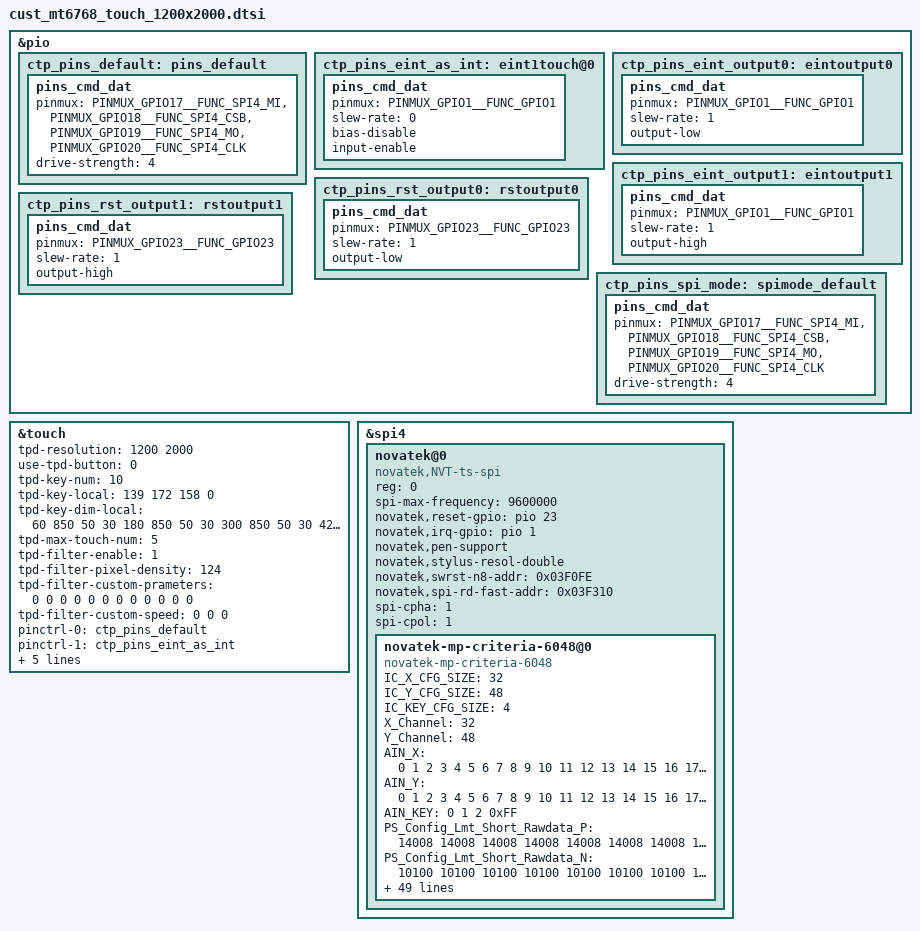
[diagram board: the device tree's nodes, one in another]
/* SPDX-License-Identifier: GPL-2.0 */
/*
 * Copyright (c) 2019 MediaTek Inc.
 *
 * This program is free software; you can redistribute it and/or modify
 * it under the terms of the GNU General Public License version 2 as
 * published by the Free Software Foundation.
 *
 * This program is distributed in the hope that it will be useful,
 * but WITHOUT ANY WARRANTY; without even the implied warranty of
 * MERCHANTABILITY or FITNESS FOR A PARTICULAR PURPOSE.  See the
 * GNU General Public License for more details.
 */
/* TOUCH start */

&pio {
	ctp_pins_default: pins_default {
		pins_cmd_dat {
			pinmux = <PINMUX_GPIO17__FUNC_SPI4_MI>,
				<PINMUX_GPIO18__FUNC_SPI4_CSB>,
				<PINMUX_GPIO19__FUNC_SPI4_MO>,
				<PINMUX_GPIO20__FUNC_SPI4_CLK>;
			drive-strength=<4>;
		};
	};
	ctp_pins_eint_as_int: eint1touch@0 {
		pins_cmd_dat {
			pinmux = <PINMUX_GPIO1__FUNC_GPIO1>;
			slew-rate = <0>;
			bias-disable;
			input-enable;
		};
	};
	ctp_pins_eint_output0: eintoutput0 {
		pins_cmd_dat {
			pinmux = <PINMUX_GPIO1__FUNC_GPIO1>;
			slew-rate = <1>;
			output-low;
		};
	};
	ctp_pins_eint_output1: eintoutput1 {
		pins_cmd_dat {
			pinmux = <PINMUX_GPIO1__FUNC_GPIO1>;
			slew-rate = <1>;
			output-high;
		};
	};
	ctp_pins_rst_output0: rstoutput0 {
		pins_cmd_dat {
			pinmux = <PINMUX_GPIO23__FUNC_GPIO23>;
			slew-rate = <1>;
			output-low;
		};
	};
	ctp_pins_rst_output1: rstoutput1 {
		pins_cmd_dat {
			pinmux = <PINMUX_GPIO23__FUNC_GPIO23>;
			slew-rate = <1>;
			output-high;
		};
	};
	ctp_pins_spi_mode: spimode_default {
		pins_cmd_dat {
			pinmux = <PINMUX_GPIO17__FUNC_SPI4_MI>,
				<PINMUX_GPIO18__FUNC_SPI4_CSB>,
				<PINMUX_GPIO19__FUNC_SPI4_MO>,
				<PINMUX_GPIO20__FUNC_SPI4_CLK>;
			drive-strength=<4>;
		};
	};
};


&touch {
	tpd-resolution = <1200 2000>;
	use-tpd-button = <0>;
	tpd-key-num = <10>;
	tpd-key-local= <139 172 158 0>;
	tpd-key-dim-local = <60 850 50 30
		180 850 50 30 300 850 50 30 420 850 50 30>;
	tpd-max-touch-num = <5>;
	tpd-filter-enable = <1>;
	tpd-filter-pixel-density = <124>;
	tpd-filter-custom-prameters = <0 0 0 0 0 0 0 0 0 0 0 0>;
	tpd-filter-custom-speed = <0 0 0>;
	pinctrl-names = "default", "state_eint_as_int", "state_eint_output0",
		"state_eint_output1", "state_rst_output0", "state_rst_output1","state_spi_mode";
	pinctrl-0 = <&ctp_pins_default>;
	pinctrl-1 = <&ctp_pins_eint_as_int>;
	pinctrl-2 = <&ctp_pins_eint_output0>;
	pinctrl-3 = <&ctp_pins_eint_output1>;
	pinctrl-4 = <&ctp_pins_rst_output0>;
	pinctrl-5 = <&ctp_pins_rst_output1>;
	pinctrl-6 = <&ctp_pins_spi_mode>;
	status = "okay";
};

&spi4 {
	status = "okay";
	#address-cells = <1>;
	#size-cells = <0>;
/*	himax_ts@0 {
		compatible = "himax,hxcommon";
		reg = <0>;
		spi-max-frequency = <10000000>;
		spi-cpha = <1>;
		spi-cpol = <1>;
	};
*/
	novatek@0 {
		compatible = "novatek,NVT-ts-spi","himax,hxcommon";
		reg = <0>; //Same as CS ID
		status = "okay";
		//4800000,9600000,15000000,19200000
		spi-max-frequency = <9600000>;

		novatek,reset-gpio = <&pio 23 0x00>;
		novatek,irq-gpio = <&pio 1 0x00>;

		novatek,pen-support;
		novatek,stylus-resol-double;

		/* 525 */
		//novatek,swrst-n8-addr = <0x01F01A>;

		/* 672A, 525B, 675, 526 */
		novatek,swrst-n8-addr = <0x03F0FE>;
		novatek,spi-rd-fast-addr = <0x03F310>;

		/* MP */
		//novatek,mp-support-dt;
		spi-cpha = <1>;
		spi-cpol = <1>;
		novatek-mp-criteria-6048@0 {
			#address-cells = <1>;
			#size-cells = <0>;
			compatible = "novatek-mp-criteria-6048";

			/* MP Config */
			IC_X_CFG_SIZE = <32>;
			IC_Y_CFG_SIZE = <48>;
			IC_KEY_CFG_SIZE = <4>;
			X_Channel = <32>;
			Y_Channel = <48>;
			AIN_X = <0 1 2 3 4 5 6 7 8 9 10 11 12 13 14 15 16 17 18 19 20 21 22 23 24 25 26 27 28 29 30 31>;
			AIN_Y = <0 1 2 3 4 5 6 7 8 9 10 11 12 13 14 15 16 17 18 19 20 21 22 23 24 25 26 27 28 29 30 31 32 33 34 35 36 37 38 39 40 41 42 43 44 45 46 47>;
			AIN_KEY = <0 1 2 0xFF>;

			/* MP Criteria */
			PS_Config_Lmt_Short_Rawdata_P = <
				14008 14008 14008 14008 14008 14008 14008 14008 14008 14008 14008 14008 14008 14008 14008 14008 14008 14008 14008 14008 14008 14008 14008 14008 14008 14008 14008 14008 14008 14008 14008 14008
				14008 14008 14008 14008 14008 14008 14008 14008 14008 14008 14008 14008 14008 14008 14008 14008 14008 14008 14008 14008 14008 14008 14008 14008 14008 14008 14008 14008 14008 14008 14008 14008
				14008 14008 14008 14008 14008 14008 14008 14008 14008 14008 14008 14008 14008 14008 14008 14008 14008 14008 14008 14008 14008 14008 14008 14008 14008 14008 14008 14008 14008 14008 14008 14008
				14008 14008 14008 14008 14008 14008 14008 14008 14008 14008 14008 14008 14008 14008 14008 14008 14008 14008 14008 14008 14008 14008 14008 14008 14008 14008 14008 14008 14008 14008 14008 14008
				14008 14008 14008 14008 14008 14008 14008 14008 14008 14008 14008 14008 14008 14008 14008 14008 14008 14008 14008 14008 14008 14008 14008 14008 14008 14008 14008 14008 14008 14008 14008 14008
				14008 14008 14008 14008 14008 14008 14008 14008 14008 14008 14008 14008 14008 14008 14008 14008 14008 14008 14008 14008 14008 14008 14008 14008 14008 14008 14008 14008 14008 14008 14008 14008
				14008 14008 14008 14008 14008 14008 14008 14008 14008 14008 14008 14008 14008 14008 14008 14008 14008 14008 14008 14008 14008 14008 14008 14008 14008 14008 14008 14008 14008 14008 14008 14008
				14008 14008 14008 14008 14008 14008 14008 14008 14008 14008 14008 14008 14008 14008 14008 14008 14008 14008 14008 14008 14008 14008 14008 14008 14008 14008 14008 14008 14008 14008 14008 14008
				14008 14008 14008 14008 14008 14008 14008 14008 14008 14008 14008 14008 14008 14008 14008 14008 14008 14008 14008 14008 14008 14008 14008 14008 14008 14008 14008 14008 14008 14008 14008 14008
				14008 14008 14008 14008 14008 14008 14008 14008 14008 14008 14008 14008 14008 14008 14008 14008 14008 14008 14008 14008 14008 14008 14008 14008 14008 14008 14008 14008 14008 14008 14008 14008
				14008 14008 14008 14008 14008 14008 14008 14008 14008 14008 14008 14008 14008 14008 14008 14008 14008 14008 14008 14008 14008 14008 14008 14008 14008 14008 14008 14008 14008 14008 14008 14008
				14008 14008 14008 14008 14008 14008 14008 14008 14008 14008 14008 14008 14008 14008 14008 14008 14008 14008 14008 14008 14008 14008 14008 14008 14008 14008 14008 14008 14008 14008 14008 14008
				14008 14008 14008 14008 14008 14008 14008 14008 14008 14008 14008 14008 14008 14008 14008 14008 14008 14008 14008 14008 14008 14008 14008 14008 14008 14008 14008 14008 14008 14008 14008 14008
				14008 14008 14008 14008 14008 14008 14008 14008 14008 14008 14008 14008 14008 14008 14008 14008 14008 14008 14008 14008 14008 14008 14008 14008 14008 14008 14008 14008 14008 14008 14008 14008
				14008 14008 14008 14008 14008 14008 14008 14008 14008 14008 14008 14008 14008 14008 14008 14008 14008 14008 14008 14008 14008 14008 14008 14008 14008 14008 14008 14008 14008 14008 14008 14008
				14008 14008 14008 14008 14008 14008 14008 14008 14008 14008 14008 14008 14008 14008 14008 14008 14008 14008 14008 14008 14008 14008 14008 14008 14008 14008 14008 14008 14008 14008 14008 14008
				14008 14008 14008 14008 14008 14008 14008 14008 14008 14008 14008 14008 14008 14008 14008 14008 14008 14008 14008 14008 14008 14008 14008 14008 14008 14008 14008 14008 14008 14008 14008 14008
				14008 14008 14008 14008 14008 14008 14008 14008 14008 14008 14008 14008 14008 14008 14008 14008 14008 14008 14008 14008 14008 14008 14008 14008 14008 14008 14008 14008 14008 14008 14008 14008
				14008 14008 14008 14008 14008 14008 14008 14008 14008 14008 14008 14008 14008 14008 14008 14008 14008 14008 14008 14008 14008 14008 14008 14008 14008 14008 14008 14008 14008 14008 14008 14008
				14008 14008 14008 14008 14008 14008 14008 14008 14008 14008 14008 14008 14008 14008 14008 14008 14008 14008 14008 14008 14008 14008 14008 14008 14008 14008 14008 14008 14008 14008 14008 14008
				14008 14008 14008 14008 14008 14008 14008 14008 14008 14008 14008 14008 14008 14008 14008 14008 14008 14008 14008 14008 14008 14008 14008 14008 14008 14008 14008 14008 14008 14008 14008 14008
				14008 14008 14008 14008 14008 14008 14008 14008 14008 14008 14008 14008 14008 14008 14008 14008 14008 14008 14008 14008 14008 14008 14008 14008 14008 14008 14008 14008 14008 14008 14008 14008
				14008 14008 14008 14008 14008 14008 14008 14008 14008 14008 14008 14008 14008 14008 14008 14008 14008 14008 14008 14008 14008 14008 14008 14008 14008 14008 14008 14008 14008 14008 14008 14008
				14008 14008 14008 14008 14008 14008 14008 14008 14008 14008 14008 14008 14008 14008 14008 14008 14008 14008 14008 14008 14008 14008 14008 14008 14008 14008 14008 14008 14008 14008 14008 14008
				14008 14008 14008 14008 14008 14008 14008 14008 14008 14008 14008 14008 14008 14008 14008 14008 14008 14008 14008 14008 14008 14008 14008 14008 14008 14008 14008 14008 14008 14008 14008 14008
				14008 14008 14008 14008 14008 14008 14008 14008 14008 14008 14008 14008 14008 14008 14008 14008 14008 14008 14008 14008 14008 14008 14008 14008 14008 14008 14008 14008 14008 14008 14008 14008
				14008 14008 14008 14008 14008 14008 14008 14008 14008 14008 14008 14008 14008 14008 14008 14008 14008 14008 14008 14008 14008 14008 14008 14008 14008 14008 14008 14008 14008 14008 14008 14008
				14008 14008 14008 14008 14008 14008 14008 14008 14008 14008 14008 14008 14008 14008 14008 14008 14008 14008 14008 14008 14008 14008 14008 14008 14008 14008 14008 14008 14008 14008 14008 14008
				14008 14008 14008 14008 14008 14008 14008 14008 14008 14008 14008 14008 14008 14008 14008 14008 14008 14008 14008 14008 14008 14008 14008 14008 14008 14008 14008 14008 14008 14008 14008 14008
				14008 14008 14008 14008 14008 14008 14008 14008 14008 14008 14008 14008 14008 14008 14008 14008 14008 14008 14008 14008 14008 14008 14008 14008 14008 14008 14008 14008 14008 14008 14008 14008
				14008 14008 14008 14008 14008 14008 14008 14008 14008 14008 14008 14008 14008 14008 14008 14008 14008 14008 14008 14008 14008 14008 14008 14008 14008 14008 14008 14008 14008 14008 14008 14008
				14008 14008 14008 14008 14008 14008 14008 14008 14008 14008 14008 14008 14008 14008 14008 14008 14008 14008 14008 14008 14008 14008 14008 14008 14008 14008 14008 14008 14008 14008 14008 14008
				14008 14008 14008 14008 14008 14008 14008 14008 14008 14008 14008 14008 14008 14008 14008 14008 14008 14008 14008 14008 14008 14008 14008 14008 14008 14008 14008 14008 14008 14008 14008 14008
				14008 14008 14008 14008 14008 14008 14008 14008 14008 14008 14008 14008 14008 14008 14008 14008 14008 14008 14008 14008 14008 14008 14008 14008 14008 14008 14008 14008 14008 14008 14008 14008
				14008 14008 14008 14008 14008 14008 14008 14008 14008 14008 14008 14008 14008 14008 14008 14008 14008 14008 14008 14008 14008 14008 14008 14008 14008 14008 14008 14008 14008 14008 14008 14008
				14008 14008 14008 14008 14008 14008 14008 14008 14008 14008 14008 14008 14008 14008 14008 14008 14008 14008 14008 14008 14008 14008 14008 14008 14008 14008 14008 14008 14008 14008 14008 14008
				14008 14008 14008 14008 14008 14008 14008 14008 14008 14008 14008 14008 14008 14008 14008 14008 14008 14008 14008 14008 14008 14008 14008 14008 14008 14008 14008 14008 14008 14008 14008 14008
				14008 14008 14008 14008 14008 14008 14008 14008 14008 14008 14008 14008 14008 14008 14008 14008 14008 14008 14008 14008 14008 14008 14008 14008 14008 14008 14008 14008 14008 14008 14008 14008
				14008 14008 14008 14008 14008 14008 14008 14008 14008 14008 14008 14008 14008 14008 14008 14008 14008 14008 14008 14008 14008 14008 14008 14008 14008 14008 14008 14008 14008 14008 14008 14008
				14008 14008 14008 14008 14008 14008 14008 14008 14008 14008 14008 14008 14008 14008 14008 14008 14008 14008 14008 14008 14008 14008 14008 14008 14008 14008 14008 14008 14008 14008 14008 14008
				14008 14008 14008 14008 14008 14008 14008 14008 14008 14008 14008 14008 14008 14008 14008 14008 14008 14008 14008 14008 14008 14008 14008 14008 14008 14008 14008 14008 14008 14008 14008 14008
				14008 14008 14008 14008 14008 14008 14008 14008 14008 14008 14008 14008 14008 14008 14008 14008 14008 14008 14008 14008 14008 14008 14008 14008 14008 14008 14008 14008 14008 14008 14008 14008
				14008 14008 14008 14008 14008 14008 14008 14008 14008 14008 14008 14008 14008 14008 14008 14008 14008 14008 14008 14008 14008 14008 14008 14008 14008 14008 14008 14008 14008 14008 14008 14008
				14008 14008 14008 14008 14008 14008 14008 14008 14008 14008 14008 14008 14008 14008 14008 14008 14008 14008 14008 14008 14008 14008 14008 14008 14008 14008 14008 14008 14008 14008 14008 14008
				14008 14008 14008 14008 14008 14008 14008 14008 14008 14008 14008 14008 14008 14008 14008 14008 14008 14008 14008 14008 14008 14008 14008 14008 14008 14008 14008 14008 14008 14008 14008 14008
				14008 14008 14008 14008 14008 14008 14008 14008 14008 14008 14008 14008 14008 14008 14008 14008 14008 14008 14008 14008 14008 14008 14008 14008 14008 14008 14008 14008 14008 14008 14008 14008
				14008 14008 14008 14008 14008 14008 14008 14008 14008 14008 14008 14008 14008 14008 14008 14008 14008 14008 14008 14008 14008 14008 14008 14008 14008 14008 14008 14008 14008 14008 14008 14008
				14008 14008 14008 14008 14008 14008 14008 14008 14008 14008 14008 14008 14008 14008 14008 14008 14008 14008 14008 14008 14008 14008 14008 14008 14008 14008 14008 14008 14008 14008 14008 14008
				14008 14008 14008>;

			PS_Config_Lmt_Short_Rawdata_N = <
				10100 10100 10100 10100 10100 10100 10100 10100 10100 10100 10100 10100 10100 10100 10100 10100 10100 10100 10100 10100 10100 10100 10100 10100 10100 10100 10100 10100 10100 10100 10100 10100
				10100 10100 10100 10100 10100 10100 10100 10100 10100 10100 10100 10100 10100 10100 10100 10100 10100 10100 10100 10100 10100 10100 10100 10100 10100 10100 10100 10100 10100 10100 10100 10100
				10100 10100 10100 10100 10100 10100 10100 10100 10100 10100 10100 10100 10100 10100 10100 10100 10100 10100 10100 10100 10100 10100 10100 10100 10100 10100 10100 10100 10100 10100 10100 10100
				10100 10100 10100 10100 10100 10100 10100 10100 10100 10100 10100 10100 10100 10100 10100 10100 10100 10100 10100 10100 10100 10100 10100 10100 10100 10100 10100 10100 10100 10100 10100 10100
				10100 10100 10100 10100 10100 10100 10100 10100 10100 10100 10100 10100 10100 10100 10100 10100 10100 10100 10100 10100 10100 10100 10100 10100 10100 10100 10100 10100 10100 10100 10100 10100
				10100 10100 10100 10100 10100 10100 10100 10100 10100 10100 10100 10100 10100 10100 10100 10100 10100 10100 10100 10100 10100 10100 10100 10100 10100 10100 10100 10100 10100 10100 10100 10100
				10100 10100 10100 10100 10100 10100 10100 10100 10100 10100 10100 10100 10100 10100 10100 10100 10100 10100 10100 10100 10100 10100 10100 10100 10100 10100 10100 10100 10100 10100 10100 10100
				10100 10100 10100 10100 10100 10100 10100 10100 10100 10100 10100 10100 10100 10100 10100 10100 10100 10100 10100 10100 10100 10100 10100 10100 10100 10100 10100 10100 10100 10100 10100 10100
				10100 10100 10100 10100 10100 10100 10100 10100 10100 10100 10100 10100 10100 10100 10100 10100 10100 10100 10100 10100 10100 10100 10100 10100 10100 10100 10100 10100 10100 10100 10100 10100
				10100 10100 10100 10100 10100 10100 10100 10100 10100 10100 10100 10100 10100 10100 10100 10100 10100 10100 10100 10100 10100 10100 10100 10100 10100 10100 10100 10100 10100 10100 10100 10100
				10100 10100 10100 10100 10100 10100 10100 10100 10100 10100 10100 10100 10100 10100 10100 10100 10100 10100 10100 10100 10100 10100 10100 10100 10100 10100 10100 10100 10100 10100 10100 10100
				10100 10100 10100 10100 10100 10100 10100 10100 10100 10100 10100 10100 10100 10100 10100 10100 10100 10100 10100 10100 10100 10100 10100 10100 10100 10100 10100 10100 10100 10100 10100 10100
				10100 10100 10100 10100 10100 10100 10100 10100 10100 10100 10100 10100 10100 10100 10100 10100 10100 10100 10100 10100 10100 10100 10100 10100 10100 10100 10100 10100 10100 10100 10100 10100
				10100 10100 10100 10100 10100 10100 10100 10100 10100 10100 10100 10100 10100 10100 10100 10100 10100 10100 10100 10100 10100 10100 10100 10100 10100 10100 10100 10100 10100 10100 10100 10100
				10100 10100 10100 10100 10100 10100 10100 10100 10100 10100 10100 10100 10100 10100 10100 10100 10100 10100 10100 10100 10100 10100 10100 10100 10100 10100 10100 10100 10100 10100 10100 10100
				10100 10100 10100 10100 10100 10100 10100 10100 10100 10100 10100 10100 10100 10100 10100 10100 10100 10100 10100 10100 10100 10100 10100 10100 10100 10100 10100 10100 10100 10100 10100 10100
				10100 10100 10100 10100 10100 10100 10100 10100 10100 10100 10100 10100 10100 10100 10100 10100 10100 10100 10100 10100 10100 10100 10100 10100 10100 10100 10100 10100 10100 10100 10100 10100
				10100 10100 10100 10100 10100 10100 10100 10100 10100 10100 10100 10100 10100 10100 10100 10100 10100 10100 10100 10100 10100 10100 10100 10100 10100 10100 10100 10100 10100 10100 10100 10100
				10100 10100 10100 10100 10100 10100 10100 10100 10100 10100 10100 10100 10100 10100 10100 10100 10100 10100 10100 10100 10100 10100 10100 10100 10100 10100 10100 10100 10100 10100 10100 10100
				10100 10100 10100 10100 10100 10100 10100 10100 10100 10100 10100 10100 10100 10100 10100 10100 10100 10100 10100 10100 10100 10100 10100 10100 10100 10100 10100 10100 10100 10100 10100 10100
				10100 10100 10100 10100 10100 10100 10100 10100 10100 10100 10100 10100 10100 10100 10100 10100 10100 10100 10100 10100 10100 10100 10100 10100 10100 10100 10100 10100 10100 10100 10100 10100
				10100 10100 10100 10100 10100 10100 10100 10100 10100 10100 10100 10100 10100 10100 10100 10100 10100 10100 10100 10100 10100 10100 10100 10100 10100 10100 10100 10100 10100 10100 10100 10100
				10100 10100 10100 10100 10100 10100 10100 10100 10100 10100 10100 10100 10100 10100 10100 10100 10100 10100 10100 10100 10100 10100 10100 10100 10100 10100 10100 10100 10100 10100 10100 10100
				10100 10100 10100 10100 10100 10100 10100 10100 10100 10100 10100 10100 10100 10100 10100 10100 10100 10100 10100 10100 10100 10100 10100 10100 10100 10100 10100 10100 10100 10100 10100 10100
				10100 10100 10100 10100 10100 10100 10100 10100 10100 10100 10100 10100 10100 10100 10100 10100 10100 10100 10100 10100 10100 10100 10100 10100 10100 10100 10100 10100 10100 10100 10100 10100
				10100 10100 10100 10100 10100 10100 10100 10100 10100 10100 10100 10100 10100 10100 10100 10100 10100 10100 10100 10100 10100 10100 10100 10100 10100 10100 10100 10100 10100 10100 10100 10100
				10100 10100 10100 10100 10100 10100 10100 10100 10100 10100 10100 10100 10100 10100 10100 10100 10100 10100 10100 10100 10100 10100 10100 10100 10100 10100 10100 10100 10100 10100 10100 10100
				10100 10100 10100 10100 10100 10100 10100 10100 10100 10100 10100 10100 10100 10100 10100 10100 10100 10100 10100 10100 10100 10100 10100 10100 10100 10100 10100 10100 10100 10100 10100 10100
				10100 10100 10100 10100 10100 10100 10100 10100 10100 10100 10100 10100 10100 10100 10100 10100 10100 10100 10100 10100 10100 10100 10100 10100 10100 10100 10100 10100 10100 10100 10100 10100
				10100 10100 10100 10100 10100 10100 10100 10100 10100 10100 10100 10100 10100 10100 10100 10100 10100 10100 10100 10100 10100 10100 10100 10100 10100 10100 10100 10100 10100 10100 10100 10100
				10100 10100 10100 10100 10100 10100 10100 10100 10100 10100 10100 10100 10100 10100 10100 10100 10100 10100 10100 10100 10100 10100 10100 10100 10100 10100 10100 10100 10100 10100 10100 10100
				10100 10100 10100 10100 10100 10100 10100 10100 10100 10100 10100 10100 10100 10100 10100 10100 10100 10100 10100 10100 10100 10100 10100 10100 10100 10100 10100 10100 10100 10100 10100 10100
				10100 10100 10100 10100 10100 10100 10100 10100 10100 10100 10100 10100 10100 10100 10100 10100 10100 10100 10100 10100 10100 10100 10100 10100 10100 10100 10100 10100 10100 10100 10100 10100
				10100 10100 10100 10100 10100 10100 10100 10100 10100 10100 10100 10100 10100 10100 10100 10100 10100 10100 10100 10100 10100 10100 10100 10100 10100 10100 10100 10100 10100 10100 10100 10100
				10100 10100 10100 10100 10100 10100 10100 10100 10100 10100 10100 10100 10100 10100 10100 10100 10100 10100 10100 10100 10100 10100 10100 10100 10100 10100 10100 10100 10100 10100 10100 10100
				10100 10100 10100 10100 10100 10100 10100 10100 10100 10100 10100 10100 10100 10100 10100 10100 10100 10100 10100 10100 10100 10100 10100 10100 10100 10100 10100 10100 10100 10100 10100 10100
				10100 10100 10100 10100 10100 10100 10100 10100 10100 10100 10100 10100 10100 10100 10100 10100 10100 10100 10100 10100 10100 10100 10100 10100 10100 10100 10100 10100 10100 10100 10100 10100
				10100 10100 10100 10100 10100 10100 10100 10100 10100 10100 10100 10100 10100 10100 10100 10100 10100 10100 10100 10100 10100 10100 10100 10100 10100 10100 10100 10100 10100 10100 10100 10100
				10100 10100 10100 10100 10100 10100 10100 10100 10100 10100 10100 10100 10100 10100 10100 10100 10100 10100 10100 10100 10100 10100 10100 10100 10100 10100 10100 10100 10100 10100 10100 10100
				10100 10100 10100 10100 10100 10100 10100 10100 10100 10100 10100 10100 10100 10100 10100 10100 10100 10100 10100 10100 10100 10100 10100 10100 10100 10100 10100 10100 10100 10100 10100 10100
				10100 10100 10100 10100 10100 10100 10100 10100 10100 10100 10100 10100 10100 10100 10100 10100 10100 10100 10100 10100 10100 10100 10100 10100 10100 10100 10100 10100 10100 10100 10100 10100
				10100 10100 10100 10100 10100 10100 10100 10100 10100 10100 10100 10100 10100 10100 10100 10100 10100 10100 10100 10100 10100 10100 10100 10100 10100 10100 10100 10100 10100 10100 10100 10100
				10100 10100 10100 10100 10100 10100 10100 10100 10100 10100 10100 10100 10100 10100 10100 10100 10100 10100 10100 10100 10100 10100 10100 10100 10100 10100 10100 10100 10100 10100 10100 10100
				10100 10100 10100 10100 10100 10100 10100 10100 10100 10100 10100 10100 10100 10100 10100 10100 10100 10100 10100 10100 10100 10100 10100 10100 10100 10100 10100 10100 10100 10100 10100 10100
				10100 10100 10100 10100 10100 10100 10100 10100 10100 10100 10100 10100 10100 10100 10100 10100 10100 10100 10100 10100 10100 10100 10100 10100 10100 10100 10100 10100 10100 10100 10100 10100
				10100 10100 10100 10100 10100 10100 10100 10100 10100 10100 10100 10100 10100 10100 10100 10100 10100 10100 10100 10100 10100 10100 10100 10100 10100 10100 10100 10100 10100 10100 10100 10100
				10100 10100 10100 10100 10100 10100 10100 10100 10100 10100 10100 10100 10100 10100 10100 10100 10100 10100 10100 10100 10100 10100 10100 10100 10100 10100 10100 10100 10100 10100 10100 10100
				10100 10100 10100 10100 10100 10100 10100 10100 10100 10100 10100 10100 10100 10100 10100 10100 10100 10100 10100 10100 10100 10100 10100 10100 10100 10100 10100 10100 10100 10100 10100 10100
				10000 10000 10000>;

			PS_Config_Lmt_Open_Rawdata_P = <
				3043 3148 3136 3074 3102 3060 3024 2976 2920 2959 3011 2997 3049 3096 3166 3203 3178 3110 3102 3098 3103 3081 3031 2973 2830 2938 2909 2973 2956 3015 3088 3171
				3064 3113 3099 3101 3019 2987 2933 2900 2846 2903 2934 2972 3014 3078 3106 3119 3115 3115 3116 3103 3035 2955 2958 2896 2772 2840 2837 2903 2940 2983 2986 3071
				3138 3164 3073 3071 3021 3032 2990 2962 2870 2973 2966 3032 3021 3075 3124 3168 3168 3157 3039 3045 3046 3036 3010 2972 2791 2892 2941 2927 2993 2976 3038 3129
				3115 3133 3064 3066 3077 2979 2945 2899 2870 2927 2931 2979 3019 3063 3137 3133 3136 3110 3066 3084 3080 2998 2913 2923 2770 2860 2864 2882 2947 2987 3033 3049
				3269 3270 3218 3127 3150 3088 3095 3067 2933 3057 3108 3115 3182 3173 3231 3250 3278 3271 3214 3091 3124 3115 3096 3089 2868 2982 3017 3085 3073 3137 3124 3196
				3194 3241 3187 3122 3141 3145 3043 3019 2979 3053 3056 3074 3127 3176 3220 3267 3238 3234 3166 3120 3164 3157 3063 2984 2896 2954 2982 3003 3019 3095 3137 3193
				3200 3292 3218 3173 3088 3116 3053 3061 2961 3015 3088 3152 3162 3239 3225 3262 3221 3271 3222 3168 3053 3095 3077 3061 2899 2959 3007 3061 3131 3126 3183 3192
				3284 3217 3197 3144 3085 3112 3105 3017 2958 3071 3085 3103 3124 3183 3232 3250 3290 3234 3185 3120 3082 3133 3117 3032 2884 2997 2982 3028 3053 3077 3148 3201
				3210 3231 3252 3179 3134 3053 3078 3024 3029 3050 3049 3136 3206 3217 3297 3259 3248 3224 3231 3182 3131 3019 3054 3047 2923 2998 2987 3052 3110 3185 3180 3257
				3267 3312 3172 3155 3105 3039 3063 3077 2983 3036 3103 3133 3155 3175 3239 3260 3263 3291 3189 3140 3078 3035 3085 3087 2889 2982 3025 3026 3074 3091 3129 3211
				3204 3235 3182 3204 3137 3091 3005 3052 3038 3109 3082 3094 3183 3259 3281 3315 3234 3249 3176 3182 3141 3092 2976 3028 2948 3021 3024 3028 3099 3162 3243 3236
				3256 3297 3267 3127 3109 3070 3001 3049 2972 3064 3067 3150 3178 3207 3239 3256 3263 3267 3242 3143 3095 3043 3003 3066 2909 2984 3008 3067 3068 3126 3157 3182
				3242 3236 3187 3140 3165 3101 3047 2951 3000 3117 3141 3127 3141 3242 3316 3297 3252 3238 3203 3136 3143 3105 3050 2914 2912 3045 3046 3066 3073 3151 3215 3297
				3203 3285 3246 3218 3087 3075 3022 2948 3017 3052 3091 3108 3197 3236 3263 3256 3215 3269 3218 3193 3099 3059 2998 2935 2921 3003 3010 3053 3109 3123 3179 3211
				3257 3273 3187 3133 3096 3129 3054 2990 2980 3081 3145 3178 3176 3197 3299 3333 3267 3257 3186 3148 3095 3102 3060 2989 2886 3005 3068 3081 3113 3123 3203 3276
				3229 3242 3241 3203 3182 3052 3035 2969 3059 3105 3085 3140 3166 3255 3292 3278 3235 3224 3218 3173 3159 3064 3017 2941 2962 3024 3035 3057 3102 3162 3182 3234
				3298 3294 3220 3151 3105 3063 3087 3005 3015 3068 3108 3199 3241 3235 3257 3312 3323 3278 3210 3147 3123 3061 3066 3004 2959 2987 3033 3115 3141 3168 3180 3259
				3218 3266 3194 3192 3164 3147 3011 2979 3010 3148 3136 3134 3190 3217 3315 3305 3250 3249 3178 3175 3133 3120 3025 2956 2927 3063 3052 3081 3106 3152 3217 3234
				3311 3323 3246 3179 3110 3064 3021 3029 3074 3092 3099 3161 3246 3295 3288 3264 3319 3326 3229 3166 3105 3082 3026 3000 2965 3045 3017 3084 3162 3196 3220 3229
				3249 3253 3215 3148 3157 3126 3105 2954 3025 3094 3175 3179 3179 3242 3266 3322 3229 3252 3200 3133 3137 3095 3082 2961 2930 3011 3091 3092 3120 3152 3204 3260
				3235 3351 3283 3197 3141 3071 3026 2965 3074 3159 3129 3143 3210 3302 3336 3292 3256 3334 3285 3186 3130 3071 3047 2961 2984 3054 3081 3059 3130 3214 3239 3263
				3287 3290 3206 3168 3110 3119 3087 3043 3022 3113 3127 3225 3234 3231 3285 3276 3280 3243 3207 3155 3095 3099 3061 3012 2921 3021 3046 3136 3144 3173 3197 3250
				3250 3276 3301 3235 3158 3102 3033 2966 3082 3162 3193 3176 3193 3266 3346 3350 3260 3273 3285 3236 3147 3094 3035 2982 3000 3075 3092 3126 3108 3180 3252 3290
				3239 3337 3241 3161 3126 3073 3084 3021 3042 3112 3147 3169 3270 3287 3271 3285 3253 3302 3194 3162 3116 3061 3067 2987 2958 3014 3053 3087 3183 3193 3207 3231
				3315 3292 3235 3257 3194 3119 3066 2972 3045 3171 3201 3238 3224 3249 3306 3347 3309 3274 3225 3241 3194 3106 3063 2965 2997 3085 3110 3137 3169 3159 3214 3295
				3217 3273 3294 3199 3123 3088 3038 3019 3061 3127 3152 3194 3222 3330 3326 3276 3238 3259 3257 3150 3120 3078 3029 2997 2968 3043 3050 3096 3129 3235 3227 3256
				3297 3361 3259 3189 3217 3158 3091 3000 3046 3133 3213 3245 3287 3280 3284 3312 3295 3330 3242 3180 3199 3162 3080 2994 2977 3085 3126 3152 3180 3222 3192 3263
				3211 3264 3238 3250 3162 3088 3063 2977 3066 3148 3168 3196 3243 3274 3371 3334 3249 3259 3222 3217 3113 3087 3059 2959 3001 3052 3085 3098 3144 3185 3271 3273
				3304 3348 3332 3217 3157 3180 3127 3024 3053 3136 3180 3262 3299 3343 3316 3294 3309 3320 3299 3204 3147 3169 3137 3008 2951 3063 3129 3178 3203 3234 3256 3243
				3253 3257 3232 3199 3215 3123 3057 2990 3108 3151 3197 3215 3248 3294 3309 3376 3276 3264 3227 3186 3179 3075 3063 2980 3033 3087 3096 3133 3147 3192 3213 3315
				3235 3350 3312 3284 3173 3113 3150 3056 3105 3137 3179 3227 3312 3350 3376 3319 3270 3323 3287 3252 3158 3105 3145 3059 3038 3031 3108 3175 3222 3248 3266 3298
				3280 3297 3225 3185 3158 3175 3096 2991 3070 3186 3199 3242 3263 3294 3327 3313 3311 3297 3235 3185 3141 3141 3054 2987 2984 3112 3130 3143 3178 3192 3222 3256
				3235 3277 3319 3264 3245 3137 3088 3077 3144 3187 3180 3218 3276 3357 3381 3376 3264 3285 3297 3242 3211 3124 3084 3067 3021 3117 3073 3147 3220 3266 3274 3312
				3255 3320 3263 3175 3141 3117 3147 3025 3091 3150 3238 3243 3292 3306 3323 3330 3291 3320 3263 3187 3138 3103 3119 2979 2983 3066 3161 3175 3185 3217 3220 3264
				3263 3278 3246 3266 3221 3201 3108 3007 3089 3227 3236 3224 3269 3318 3386 3386 3276 3283 3256 3248 3197 3175 3098 3010 2996 3099 3164 3117 3190 3256 3295 3316
				3248 3302 3292 3213 3137 3105 3094 3068 3029 3169 3199 3281 3290 3332 3339 3325 3273 3309 3295 3221 3148 3108 3082 3045 2956 3063 3110 3203 3218 3225 3243 3262
				3283 3309 3250 3206 3231 3186 3179 3032 3102 3129 3278 3281 3273 3306 3353 3389 3311 3291 3253 3215 3208 3165 3158 3029 3046 3028 3148 3208 3162 3228 3288 3341
				3222 3290 3274 3252 3173 3099 3080 3017 3056 3068 3218 3245 3334 3329 3364 3344 3267 3291 3284 3256 3180 3113 3087 3012 2987 2994 3108 3157 3252 3259 3255 3287
				3299 3322 3280 3208 3165 3190 3159 3098 3105 3144 3173 3326 3333 3311 3336 3355 3337 3319 3266 3213 3173 3171 3141 3088 3040 3081 3073 3194 3255 3197 3255 3332
				3231 3260 3262 3228 3210 3131 3077 3003 3064 3094 3113 3259 3292 3367 3365 3369 3294 3278 3262 3239 3210 3144 3092 3018 2965 3021 3038 3151 3197 3281 3285 3292
				3301 3346 3297 3241 3171 3127 3169 3081 3091 3140 3186 3210 3371 3365 3340 3339 3348 3355 3295 3227 3175 3143 3150 3078 3014 3074 3122 3109 3235 3288 3227 3298
				3236 3270 3231 3222 3189 3168 3108 2997 3094 3099 3136 3150 3301 3323 3399 3367 3241 3305 3250 3222 3199 3175 3124 3024 3010 2994 3060 3074 3187 3228 3311 3325
				3294 3334 3309 3250 3193 3124 3098 3084 3088 3124 3180 3228 3257 3397 3389 3337 3323 3355 3320 3250 3179 3133 3116 3084 3004 3043 3116 3159 3150 3262 3309 3262
				3221 3277 3241 3189 3179 3145 3144 3028 3073 3130 3138 3173 3193 3329 3354 3400 3276 3249 3278 3213 3179 3159 3145 3054 3007 3046 3035 3096 3116 3211 3253 3346
				3112 3221 3189 3154 3095 3039 2990 2907 2965 3011 3056 3109 3159 3201 3311 3273 3178 3220 3211 3169 3095 3029 2998 2933 2940 2928 2977 3043 3089 3095 3176 3236
				3178 3148 3130 3084 3033 3025 3007 2951 2973 2994 3060 3067 3103 3134 3242 3241 3224 3173 3109 3126 3054 3025 3019 2962 2902 2930 2976 2966 3031 3057 3126 3183
				3138 3150 3192 3150 3112 3056 3014 2912 3024 3004 3054 3096 3157 3217 3229 3301 3144 3187 3192 3176 3126 3059 3007 2933 2933 2980 2969 3015 3087 3147 3119 3213
				3161 3236 3147 3124 3068 3024 3032 2965 3001 3039 3068 3129 3141 3192 3193 3271 3218 3259 3178 3108 3115 3052 3040 2991 2917 2962 2996 3035 3035 3112 3113 3197
				5120 5120 5120>;

			PS_Config_Lmt_Open_Rawdata_N = <
				1304 1349 1344 1317 1329 1311 1296 1275 1251 1268 1290 1284 1306 1327 1357 1372 1362 1333 1329 1327 1330 1320 1299 1274 1213 1259 1246 1274 1267 1292 1323 1359
				1313 1334 1328 1329 1294 1280 1257 1243 1219 1244 1257 1273 1291 1319 1331 1336 1335 1335 1335 1330 1300 1266 1267 1241 1188 1217 1216 1244 1260 1278 1279 1316
				1345 1356 1317 1316 1294 1299 1281 1269 1230 1274 1271 1299 1294 1318 1339 1357 1357 1353 1302 1305 1305 1301 1290 1273 1196 1239 1260 1254 1282 1275 1302 1341
				1335 1342 1313 1314 1318 1276 1262 1242 1230 1254 1256 1276 1294 1312 1344 1342 1344 1333 1314 1321 1320 1285 1248 1252 1187 1225 1227 1235 1263 1280 1300 1306
				1401 1401 1379 1340 1350 1323 1326 1314 1257 1310 1332 1335 1363 1360 1384 1393 1405 1402 1377 1324 1339 1335 1327 1324 1229 1278 1293 1322 1317 1344 1339 1369
				1369 1389 1366 1338 1346 1348 1304 1294 1276 1308 1309 1317 1340 1361 1380 1400 1387 1386 1357 1337 1356 1353 1312 1279 1241 1266 1278 1287 1294 1326 1344 1368
				1371 1411 1379 1360 1323 1335 1308 1312 1269 1292 1323 1351 1355 1388 1382 1398 1380 1402 1381 1357 1308 1326 1318 1312 1242 1268 1288 1312 1342 1339 1364 1368
				1407 1378 1370 1347 1322 1333 1330 1293 1267 1316 1322 1330 1339 1364 1385 1393 1410 1386 1365 1337 1321 1342 1336 1299 1236 1284 1278 1297 1308 1318 1349 1372
				1375 1384 1393 1362 1343 1308 1319 1296 1298 1307 1306 1344 1374 1378 1413 1396 1392 1381 1384 1363 1342 1294 1309 1306 1252 1285 1280 1308 1333 1365 1363 1396
				1400 1419 1359 1352 1330 1302 1312 1318 1278 1301 1330 1342 1352 1360 1388 1397 1398 1410 1366 1345 1319 1300 1322 1323 1238 1278 1296 1297 1317 1324 1341 1376
				1373 1386 1363 1373 1344 1324 1288 1308 1302 1332 1321 1326 1364 1396 1406 1420 1386 1392 1361 1363 1346 1325 1275 1297 1263 1294 1296 1297 1328 1355 1390 1387
				1395 1413 1400 1340 1332 1315 1286 1306 1273 1313 1314 1350 1362 1374 1388 1395 1398 1400 1389 1347 1326 1304 1287 1314 1246 1279 1289 1314 1315 1339 1353 1363
				1389 1387 1366 1345 1356 1329 1306 1264 1285 1336 1346 1340 1346 1389 1421 1413 1393 1387 1372 1344 1347 1330 1307 1249 1248 1305 1305 1314 1317 1350 1378 1413
				1372 1408 1391 1379 1323 1318 1295 1263 1293 1308 1324 1332 1370 1387 1398 1395 1378 1401 1379 1368 1328 1311 1285 1258 1252 1287 1290 1308 1332 1338 1362 1376
				1396 1402 1366 1342 1327 1341 1309 1281 1277 1320 1348 1362 1361 1370 1414 1428 1400 1396 1365 1349 1326 1329 1311 1281 1237 1288 1315 1320 1334 1338 1372 1404
				1384 1389 1389 1372 1363 1308 1300 1272 1311 1330 1322 1345 1357 1395 1411 1405 1386 1381 1379 1360 1354 1313 1293 1260 1269 1296 1300 1310 1329 1355 1363 1386
				1413 1411 1380 1350 1330 1312 1323 1288 1292 1315 1332 1371 1389 1386 1396 1419 1424 1405 1375 1348 1338 1312 1314 1287 1268 1280 1300 1335 1346 1357 1363 1396
				1379 1399 1369 1368 1356 1348 1290 1276 1290 1349 1344 1343 1367 1378 1420 1416 1393 1392 1362 1360 1342 1337 1296 1267 1254 1312 1308 1320 1331 1351 1378 1386
				1419 1424 1391 1362 1333 1313 1294 1298 1317 1325 1328 1354 1391 1412 1409 1399 1422 1425 1384 1357 1330 1321 1297 1285 1270 1305 1293 1321 1355 1369 1380 1384
				1392 1394 1378 1349 1353 1339 1330 1266 1296 1326 1360 1362 1362 1389 1399 1423 1384 1393 1371 1342 1344 1326 1321 1269 1255 1290 1324 1325 1337 1351 1373 1397
				1386 1436 1407 1370 1346 1316 1297 1270 1317 1354 1341 1347 1375 1415 1429 1411 1395 1429 1408 1365 1341 1316 1306 1269 1279 1309 1320 1311 1341 1377 1388 1398
				1408 1410 1374 1357 1333 1336 1323 1304 1295 1334 1340 1382 1386 1384 1408 1404 1405 1390 1374 1352 1326 1328 1312 1291 1252 1294 1305 1344 1347 1360 1370 1393
				1393 1404 1414 1386 1353 1329 1300 1271 1321 1355 1368 1361 1368 1399 1434 1435 1397 1402 1408 1387 1348 1326 1300 1278 1285 1318 1325 1339 1332 1363 1393 1410
				1388 1430 1389 1354 1339 1317 1321 1294 1303 1333 1348 1358 1401 1408 1402 1408 1394 1415 1369 1355 1335 1312 1314 1280 1267 1291 1308 1323 1364 1368 1374 1384
				1420 1411 1386 1396 1369 1336 1314 1273 1305 1359 1372 1387 1381 1392 1417 1434 1418 1403 1382 1389 1369 1331 1312 1270 1284 1322 1333 1344 1358 1354 1377 1412
				1378 1402 1411 1371 1338 1323 1302 1294 1312 1340 1351 1369 1381 1427 1425 1404 1387 1396 1396 1350 1337 1319 1298 1284 1272 1304 1307 1327 1341 1386 1383 1395
				1413 1440 1396 1366 1378 1353 1324 1285 1305 1342 1377 1390 1408 1405 1407 1419 1412 1427 1389 1363 1371 1355 1320 1283 1276 1322 1339 1351 1363 1381 1368 1398
				1376 1399 1387 1393 1355 1323 1312 1276 1314 1349 1357 1369 1390 1403 1444 1429 1392 1396 1381 1378 1334 1323 1311 1268 1286 1308 1322 1327 1347 1365 1402 1402
				1416 1435 1428 1378 1353 1363 1340 1296 1308 1344 1363 1398 1414 1432 1421 1411 1418 1423 1414 1373 1348 1358 1344 1289 1264 1312 1341 1362 1372 1386 1395 1390
				1394 1396 1385 1371 1378 1338 1310 1281 1332 1350 1370 1378 1392 1411 1418 1447 1404 1399 1383 1365 1362 1318 1312 1277 1300 1323 1327 1342 1348 1368 1377 1420
				1386 1435 1419 1407 1360 1334 1350 1309 1330 1344 1362 1383 1419 1435 1447 1422 1401 1424 1408 1393 1353 1330 1348 1311 1302 1299 1332 1360 1381 1392 1399 1413
				1405 1413 1382 1365 1353 1360 1327 1282 1315 1365 1371 1389 1398 1411 1426 1420 1419 1413 1386 1365 1346 1346 1309 1280 1279 1333 1341 1347 1362 1368 1381 1395
				1386 1404 1422 1399 1390 1344 1323 1318 1347 1366 1363 1379 1404 1438 1449 1447 1399 1408 1413 1389 1376 1339 1321 1314 1294 1336 1317 1348 1380 1399 1403 1419
				1395 1423 1398 1360 1346 1336 1348 1296 1324 1350 1387 1390 1411 1417 1424 1427 1410 1423 1398 1366 1345 1330 1336 1276 1278 1314 1354 1360 1365 1378 1380 1399
				1398 1405 1391 1399 1380 1372 1332 1288 1324 1383 1387 1381 1401 1422 1451 1451 1404 1407 1395 1392 1370 1360 1327 1290 1284 1328 1356 1336 1367 1395 1412 1421
				1392 1415 1411 1377 1344 1330 1326 1315 1298 1358 1371 1406 1410 1428 1431 1425 1402 1418 1412 1380 1349 1332 1321 1305 1267 1312 1333 1372 1379 1382 1390 1398
				1407 1418 1393 1374 1384 1365 1362 1299 1329 1341 1405 1406 1402 1417 1437 1452 1419 1410 1394 1378 1375 1356 1353 1298 1305 1297 1349 1375 1355 1383 1409 1432
				1381 1410 1403 1393 1360 1328 1320 1293 1309 1315 1379 1390 1429 1426 1441 1433 1400 1410 1407 1395 1363 1334 1323 1291 1280 1283 1332 1353 1393 1396 1395 1408
				1414 1423 1405 1375 1356 1367 1354 1327 1330 1347 1360 1425 1428 1419 1429 1438 1430 1422 1399 1377 1360 1359 1346 1323 1303 1320 1317 1369 1395 1370 1395 1428
				1384 1397 1398 1383 1375 1342 1318 1287 1313 1326 1334 1396 1411 1443 1442 1444 1411 1405 1398 1388 1375 1347 1325 1293 1270 1294 1302 1350 1370 1406 1408 1411
				1414 1434 1413 1389 1359 1340 1358 1320 1324 1345 1365 1375 1444 1442 1431 1431 1435 1438 1412 1383 1360 1347 1350 1319 1291 1317 1338 1332 1386 1409 1383 1413
				1387 1401 1384 1381 1366 1357 1332 1284 1326 1328 1344 1350 1414 1424 1456 1443 1389 1416 1393 1381 1371 1360 1339 1296 1290 1283 1311 1317 1366 1383 1419 1425
				1411 1429 1418 1393 1368 1339 1327 1321 1323 1339 1363 1383 1396 1456 1452 1430 1424 1438 1423 1393 1362 1342 1335 1321 1287 1304 1335 1354 1350 1398 1418 1398
				1380 1404 1389 1366 1362 1348 1347 1297 1317 1341 1345 1360 1368 1426 1437 1457 1404 1392 1405 1377 1362 1354 1348 1309 1288 1305 1300 1327 1335 1376 1394 1434
				1333 1380 1366 1351 1326 1302 1281 1246 1270 1290 1309 1332 1354 1372 1419 1402 1362 1380 1376 1358 1326 1298 1285 1257 1260 1255 1276 1304 1324 1326 1361 1387
				1362 1349 1341 1321 1300 1296 1288 1264 1274 1283 1311 1314 1330 1343 1389 1389 1381 1360 1332 1339 1309 1296 1294 1269 1243 1255 1275 1271 1299 1310 1339 1364
				1345 1350 1368 1350 1333 1309 1291 1248 1296 1287 1309 1327 1353 1378 1384 1414 1347 1366 1368 1361 1339 1311 1288 1257 1257 1277 1272 1292 1323 1348 1336 1377
				1354 1387 1348 1339 1315 1296 1299 1270 1286 1302 1315 1341 1346 1368 1368 1402 1379 1396 1362 1332 1335 1308 1303 1282 1250 1269 1284 1300 1300 1333 1334 1370
				(-511) (-511) (-511)>;

			PS_Config_Lmt_FW_Rawdata_P = <
				1104 1113 1124 1117 1097 1113 1111 1114 1118 1128 1127 1118 1117 1113 1117 1121 1114 1129 1121 1099 1103 1114 1111 1108 1131 1106 1101 1118 1113 1127 1115 1103
				1121 1127 1108 1128 1110 1122 1128 1118 1120 1125 1132 1117 1118 1118 1106 1113 1124 1107 1111 1128 1121 1129 1110 1128 1131 1128 1124 1110 1115 1118 1118 1121
				1120 1113 1117 1106 1107 1111 1129 1113 1104 1120 1118 1114 1111 1108 1122 1107 1115 1118 1107 1120 1114 1114 1125 1121 1108 1117 1103 1107 1127 1122 1115 1121
				1132 1113 1122 1110 1121 1114 1132 1114 1108 1118 1122 1122 1111 1110 1117 1118 1118 1106 1100 1107 1135 1122 1122 1118 1122 1121 1104 1129 1107 1115 1114 1117
				1115 1103 1122 1117 1114 1113 1120 1099 1114 1111 1121 1120 1108 1118 1118 1101 1111 1120 1131 1097 1113 1121 1110 1117 1107 1100 1120 1113 1117 1113 1129 1127
				1111 1101 1120 1127 1117 1110 1121 1094 1103 1108 1127 1121 1107 1114 1111 1120 1114 1121 1120 1101 1117 1136 1115 1111 1124 1129 1129 1103 1113 1113 1122 1114
				1113 1114 1103 1122 1113 1115 1117 1124 1107 1113 1114 1115 1108 1115 1118 1115 1107 1117 1115 1125 1099 1106 1117 1121 1118 1101 1099 1118 1121 1117 1108 1129
				1129 1127 1106 1122 1121 1115 1108 1125 1129 1114 1108 1128 1114 1107 1111 1113 1114 1138 1122 1111 1097 1114 1139 1108 1108 1125 1129 1131 1106 1110 1115 1124
				1114 1117 1115 1101 1125 1107 1117 1125 1129 1110 1111 1118 1118 1115 1115 1128 1096 1121 1127 1120 1125 1104 1106 1111 1122 1115 1101 1103 1122 1128 1122 1113
				1118 1121 1114 1110 1125 1125 1118 1115 1127 1115 1115 1118 1131 1110 1107 1108 1128 1106 1135 1114 1107 1096 1117 1134 1135 1110 1125 1121 1122 1100 1111 1115
				1110 1127 1114 1115 1104 1129 1114 1127 1120 1118 1108 1113 1117 1120 1113 1115 1114 1097 1120 1122 1121 1120 1099 1106 1115 1115 1113 1104 1110 1127 1132 1131
				1122 1129 1122 1118 1110 1118 1113 1124 1128 1108 1111 1114 1118 1122 1117 1110 1104 1120 1099 1131 1108 1110 1103 1118 1128 1138 1113 1125 1117 1117 1106 1106
				1125 1117 1113 1104 1117 1104 1124 1108 1101 1120 1127 1110 1117 1114 1108 1113 1127 1106 1111 1114 1120 1121 1122 1107 1115 1120 1118 1117 1113 1110 1114 1118
				1127 1132 1121 1121 1122 1106 1124 1124 1111 1121 1115 1115 1118 1113 1120 1120 1111 1107 1111 1111 1131 1108 1111 1090 1104 1127 1134 1110 1128 1117 1122 1107
				1120 1114 1104 1110 1107 1118 1115 1131 1111 1107 1117 1117 1103 1114 1111 1110 1125 1118 1101 1117 1111 1117 1115 1117 1127 1121 1120 1115 1117 1111 1111 1106
				1103 1114 1128 1124 1125 1120 1111 1115 1110 1106 1120 1111 1113 1117 1115 1111 1110 1124 1120 1111 1108 1131 1111 1106 1121 1110 1128 1136 1113 1131 1121 1129
				1121 1101 1124 1104 1107 1111 1121 1106 1129 1110 1104 1114 1100 1108 1113 1107 1114 1121 1117 1103 1122 1108 1117 1120 1114 1132 1117 1120 1120 1121 1113 1122
				1122 1120 1107 1122 1122 1128 1110 1108 1127 1120 1103 1125 1124 1111 1115 1117 1113 1110 1121 1124 1108 1113 1131 1114 1120 1125 1104 1125 1117 1118 1115 1117
				1124 1125 1104 1120 1110 1107 1110 1117 1120 1127 1108 1110 1114 1114 1107 1110 1114 1113 1121 1113 1111 1125 1117 1115 1118 1118 1134 1118 1117 1121 1124 1104
				1117 1101 1122 1107 1117 1113 1127 1122 1108 1132 1114 1104 1135 1117 1120 1115 1120 1110 1108 1121 1124 1107 1101 1125 1110 1120 1121 1101 1121 1132 1113 1128
				1108 1111 1127 1106 1121 1113 1103 1111 1115 1124 1127 1108 1113 1113 1114 1111 1114 1129 1118 1124 1113 1101 1115 1114 1128 1110 1120 1132 1127 1121 1128 1106
				1118 1120 1108 1128 1108 1118 1110 1125 1125 1107 1128 1114 1103 1134 1118 1113 1121 1120 1107 1106 1121 1128 1111 1108 1111 1114 1124 1115 1106 1121 1139 1107
				1114 1117 1106 1127 1110 1120 1118 1104 1114 1124 1125 1127 1114 1113 1121 1135 1113 1118 1122 1110 1118 1111 1103 1118 1124 1115 1114 1121 1132 1131 1120 1114
				1121 1124 1110 1108 1125 1110 1117 1113 1132 1115 1104 1125 1117 1104 1131 1115 1132 1125 1122 1106 1107 1122 1110 1108 1114 1118 1114 1122 1113 1113 1107 1136
				1099 1114 1124 1111 1127 1108 1121 1113 1125 1108 1125 1124 1127 1106 1106 1120 1124 1113 1108 1121 1110 1122 1120 1104 1118 1117 1113 1118 1113 1113 1134 1115
				1120 1107 1127 1114 1115 1124 1104 1114 1118 1110 1115 1110 1122 1117 1106 1120 1113 1117 1124 1125 1108 1107 1120 1120 1125 1124 1121 1110 1121 1114 1118 1103
				1111 1125 1115 1129 1110 1121 1117 1124 1122 1120 1115 1127 1121 1114 1110 1113 1118 1124 1117 1115 1113 1111 1124 1120 1111 1122 1117 1117 1115 1115 1107 1135
				1106 1121 1108 1121 1117 1113 1128 1115 1110 1120 1117 1117 1117 1124 1125 1111 1136 1114 1114 1122 1122 1110 1117 1118 1103 1128 1122 1128 1115 1124 1118 1124
				1134 1121 1124 1121 1134 1108 1125 1110 1124 1107 1122 1108 1131 1124 1118 1115 1115 1127 1122 1122 1114 1113 1113 1127 1132 1114 1115 1121 1110 1115 1111 1118
				1118 1132 1111 1111 1136 1115 1114 1125 1107 1117 1125 1113 1122 1122 1115 1129 1118 1135 1115 1120 1121 1113 1127 1121 1111 1120 1124 1128 1125 1111 1131 1117
				1122 1093 1122 1128 1120 1136 1108 1129 1129 1117 1108 1114 1107 1134 1127 1118 1117 1121 1122 1121 1118 1111 1118 1113 1117 1142 1115 1117 1115 1113 1114 1114
				1117 1106 1131 1120 1117 1134 1118 1114 1110 1111 1114 1117 1113 1121 1121 1118 1121 1122 1131 1120 1106 1114 1124 1128 1117 1107 1121 1124 1128 1127 1106 1131
				1128 1121 1096 1124 1129 1128 1128 1106 1120 1104 1111 1106 1117 1106 1135 1124 1132 1115 1114 1114 1121 1121 1114 1124 1134 1108 1142 1118 1114 1124 1115 1124
				1122 1118 1106 1129 1118 1120 1122 1120 1145 1117 1108 1111 1118 1108 1127 1125 1136 1131 1121 1135 1120 1104 1124 1117 1117 1122 1113 1127 1122 1121 1128 1108
				1135 1104 1127 1100 1127 1134 1122 1124 1111 1127 1111 1117 1096 1113 1107 1128 1129 1125 1118 1110 1110 1118 1127 1122 1115 1127 1107 1148 1121 1110 1122 1124
				1121 1125 1124 1106 1131 1121 1121 1129 1124 1132 1114 1108 1118 1118 1113 1120 1127 1135 1131 1122 1122 1122 1107 1122 1115 1101 1118 1108 1122 1115 1124 1134
				1122 1118 1094 1125 1099 1125 1134 1124 1125 1108 1120 1103 1110 1104 1114 1104 1125 1132 1120 1114 1111 1111 1131 1128 1128 1118 1132 1115 1146 1114 1111 1111
				1124 1118 1121 1121 1108 1129 1114 1121 1121 1118 1132 1115 1111 1122 1114 1106 1106 1122 1136 1128 1125 1125 1122 1108 1120 1113 1100 1120 1108 1125 1114 1124
				1127 1120 1122 1106 1127 1100 1131 1131 1118 1124 1114 1121 1101 1110 1104 1111 1115 1118 1131 1127 1114 1113 1114 1125 1125 1131 1107 1129 1117 1142 1120 1113
				1125 1113 1115 1118 1122 1107 1134 1118 1122 1115 1120 1128 1117 1114 1124 1108 1114 1113 1121 1135 1124 1124 1115 1134 1120 1117 1115 1099 1121 1111 1127 1118
				1122 1129 1118 1124 1121 1122 1106 1132 1131 1118 1131 1115 1122 1101 1120 1111 1125 1113 1111 1132 1127 1118 1110 1113 1125 1120 1128 1110 1114 1118 1148 1128
				1121 1115 1114 1113 1129 1118 1115 1125 1104 1127 1115 1120 1131 1113 1100 1132 1120 1114 1127 1121 1131 1120 1127 1101 1118 1121 1115 1114 1094 1121 1111 1108
				1136 1129 1127 1121 1132 1118 1117 1104 1120 1131 1110 1136 1106 1118 1125 1117 1113 1118 1120 1111 1125 1122 1113 1114 1114 1124 1120 1118 1115 1131 1113 1141
				1125 1121 1124 1115 1118 1134 1121 1117 1132 1111 1128 1113 1111 1138 1106 1107 1121 1118 1117 1134 1120 1132 1115 1125 1108 1108 1113 1106 1110 1120 1120 1115
				1117 1122 1117 1122 1127 1117 1131 1131 1117 1114 1111 1131 1120 1103 1122 1142 1110 1125 1121 1121 1128 1108 1120 1110 1111 1118 1117 1113 1106 1124 1121 1124
				1118 1117 1111 1125 1124 1131 1124 1128 1113 1110 1128 1122 1118 1106 1114 1104 1113 1125 1113 1117 1121 1110 1124 1100 1125 1124 1120 1124 1118 1111 1131 1115
				1104 1127 1138 1118 1103 1122 1120 1134 1111 1100 1110 1108 1124 1114 1120 1115 1110 1113 1124 1117 1117 1134 1110 1124 1128 1110 1141 1114 1118 1113 1125 1125
				1122 1122 1122 1111 1121 1129 1120 1128 1125 1113 1124 1113 1136 1121 1110 1132 1117 1131 1127 1129 1121 1128 1120 1113 1114 1135 1113 1111 1124 1106 1101 1107
				3840 3840 3840>;

			PS_Config_Lmt_FW_Rawdata_N = <
				473 477 481 478 470 477 476 477 479 483 483 479 478 477 478 480 477 484 480 471 472 477 476 475 484 474 472 479 477 483 478 472
				480 483 475 483 475 481 483 479 480 482 485 478 479 479 474 477 481 474 476 483 480 484 475 483 484 483 481 475 478 479 479 480
				480 477 478 474 474 476 484 477 473 480 479 477 476 475 481 474 478 479 474 480 477 477 482 480 475 478 472 474 483 481 478 480
				485 477 481 475 480 477 485 477 475 479 481 481 476 475 478 479 479 474 471 474 486 481 481 479 481 480 473 484 474 478 477 478
				478 472 481 478 477 477 480 471 477 476 480 480 475 479 479 472 476 480 484 470 477 480 475 478 474 471 480 477 478 477 484 483
				476 472 480 483 478 475 480 469 472 475 483 480 474 477 476 480 477 480 480 472 478 487 478 476 481 484 484 472 477 477 481 477
				477 477 472 481 477 478 478 481 474 477 477 478 475 478 479 478 474 478 478 482 471 474 478 480 479 472 471 479 480 478 475 484
				484 483 474 481 480 478 475 482 484 477 475 483 477 474 476 477 477 487 481 476 470 477 488 475 475 482 484 484 474 475 478 481
				477 478 478 472 482 474 478 482 484 475 476 479 479 478 478 483 469 480 483 480 482 473 474 476 481 478 472 472 481 483 481 477
				479 480 477 475 482 482 479 478 483 478 478 479 484 475 474 475 483 474 486 477 474 469 478 486 486 475 482 480 481 471 476 478
				475 483 477 478 473 484 477 483 480 479 475 477 478 480 477 478 477 470 480 481 480 480 471 474 478 478 477 473 475 483 485 484
				481 484 481 479 475 479 477 481 483 475 476 477 479 481 478 475 473 480 471 484 475 475 472 479 483 487 477 482 478 478 474 474
				482 478 477 473 478 473 481 475 472 480 483 475 478 477 475 477 483 474 476 477 480 480 481 474 478 480 479 478 477 475 477 479
				483 485 480 480 481 474 481 481 476 480 478 478 479 477 480 480 476 474 476 476 484 475 476 467 473 483 486 475 483 478 481 474
				480 477 473 475 474 479 478 484 476 474 478 478 472 477 476 475 482 479 472 478 476 478 478 478 483 480 480 478 478 476 476 474
				472 477 483 481 482 480 476 478 475 474 480 476 477 478 478 476 475 481 480 476 475 484 476 474 480 475 483 487 477 484 480 484
				480 472 481 473 474 476 480 474 484 475 473 477 471 475 477 474 477 480 478 472 481 475 478 480 477 485 478 480 480 480 477 481
				481 480 474 481 481 483 475 475 483 480 472 482 481 476 478 478 477 475 480 481 475 477 484 477 480 482 473 482 478 479 478 478
				481 482 473 480 475 474 475 478 480 483 475 475 477 477 474 475 477 477 480 477 476 482 478 478 479 479 486 479 478 480 481 473
				478 472 481 474 478 477 483 481 475 485 477 473 486 478 480 478 480 475 475 480 481 474 472 482 475 480 480 472 480 485 477 483
				475 476 483 474 480 477 472 476 478 481 483 475 477 477 477 476 477 484 479 481 477 472 478 477 483 475 480 485 483 480 483 474
				479 480 475 483 475 479 475 482 482 474 483 477 472 486 479 477 480 480 474 474 480 483 476 475 476 477 481 478 474 480 488 474
				477 478 474 483 475 480 479 473 477 481 482 483 477 477 480 486 477 479 481 475 479 476 472 479 481 478 477 480 485 484 480 477
				480 481 475 475 482 475 478 477 485 478 473 482 478 473 484 478 485 482 481 474 474 481 475 475 477 479 477 481 477 477 474 487
				471 477 481 476 483 475 480 477 482 475 482 481 483 474 474 480 481 477 475 480 475 481 480 473 479 478 477 479 477 477 486 478
				480 474 483 477 478 481 473 477 479 475 478 475 481 478 474 480 477 478 481 482 475 474 480 480 482 481 480 475 480 477 479 472
				476 482 478 484 475 480 478 481 481 480 478 483 480 477 475 477 479 481 478 478 477 476 481 480 476 481 478 478 478 478 474 486
				474 480 475 480 478 477 483 478 475 480 478 478 478 481 482 476 487 477 477 481 481 475 478 479 472 483 481 483 478 481 479 481
				486 480 481 480 486 475 482 475 481 474 481 475 484 481 479 478 478 483 481 481 477 477 477 483 485 477 478 480 475 478 476 479
				479 485 476 476 487 478 477 482 474 478 482 477 481 481 478 484 479 486 478 480 480 477 483 480 476 480 481 483 482 476 484 478
				481 468 481 483 480 487 475 484 484 478 475 477 474 486 483 479 478 480 481 480 479 476 479 477 478 489 478 478 478 477 477 477
				478 474 484 480 478 486 479 477 475 476 477 478 477 480 480 479 480 481 484 480 474 477 481 483 478 474 480 481 483 483 474 484
				483 480 469 481 484 483 483 474 480 473 476 474 478 474 486 481 485 478 477 477 480 480 477 481 486 475 489 479 477 481 478 481
				481 479 474 484 479 480 481 480 490 478 475 476 479 475 483 482 487 484 480 486 480 473 481 478 478 481 477 483 481 480 483 475
				486 473 483 471 483 486 481 481 476 483 476 478 469 477 474 483 484 482 479 475 475 479 483 481 478 483 474 492 480 475 481 481
				480 482 481 474 484 480 480 484 481 485 477 475 479 479 477 480 483 486 484 481 481 481 474 481 478 472 479 475 481 478 481 486
				481 479 469 482 471 482 486 481 482 475 480 472 475 473 477 473 482 485 480 477 476 476 484 483 483 479 485 478 491 477 476 476
				481 479 480 480 475 484 477 480 480 479 485 478 476 481 477 474 474 481 487 483 482 482 481 475 480 477 471 480 475 482 477 481
				483 480 481 474 483 471 484 484 479 481 477 480 472 475 473 476 478 479 484 483 477 477 477 482 482 484 474 484 478 489 480 477
				482 477 478 479 481 474 486 479 481 478 480 483 478 477 481 475 477 477 480 486 481 481 478 486 480 478 478 471 480 476 483 479
				481 484 479 481 480 481 474 485 484 479 484 478 481 472 480 476 482 477 476 485 483 479 475 477 482 480 483 475 477 479 492 483
				480 478 477 477 484 479 478 482 473 483 478 480 484 477 471 485 480 477 483 480 484 480 483 472 479 480 478 477 469 480 476 475
				487 484 483 480 485 479 478 473 480 484 475 487 474 479 482 478 477 479 480 476 482 481 477 477 477 481 480 479 478 484 477 489
				482 480 481 478 479 486 480 478 485 476 483 477 476 487 474 474 480 479 478 486 480 485 478 482 475 475 477 474 475 480 480 478
				478 481 478 481 483 478 484 484 478 477 476 484 480 472 481 489 475 482 480 480 483 475 480 475 476 479 478 477 474 481 480 481
				479 478 476 482 481 484 481 483 477 475 483 481 479 474 477 473 477 482 477 478 480 475 481 471 482 481 480 481 479 476 484 478
				473 483 487 479 472 481 480 486 476 471 475 475 481 477 480 478 475 477 481 478 478 486 475 481 483 475 489 477 479 477 482 482
				481 481 481 476 480 484 480 483 482 477 481 477 487 480 475 485 478 484 483 484 480 483 480 477 477 486 477 476 481 474 472 474
				240 240 240>;

			PS_Config_Lmt_FW_CC_P = <
				75 66 71 71 73 73 73 73 73 73 71 71 71 73 73 74 75 66 71 71 74 73 73 73 73 73 73 73 71 71 73 75
				71 66 69 71 70 70 70 70 71 70 70 70 70 70 71 70 70 66 70 71 71 70 71 70 71 70 70 70 70 70 70 71
				71 71 64 70 70 73 71 71 71 71 71 70 71 71 71 71 71 71 66 70 70 73 71 71 71 71 71 71 71 70 71 73
				71 69 66 69 71 71 70 70 71 71 70 70 70 70 71 71 71 70 66 70 71 71 70 71 71 71 70 70 70 70 70 73
				73 70 71 66 70 70 73 73 71 71 71 73 71 71 71 71 71 71 71 66 70 70 73 73 71 71 71 73 71 71 71 73
				71 71 70 66 70 71 71 71 73 71 71 70 70 70 71 71 70 71 70 66 70 71 71 70 71 71 71 70 70 70 70 73
				71 71 70 71 66 70 70 73 71 71 71 71 73 71 71 71 71 71 71 71 66 70 70 73 71 71 71 71 73 71 71 73
				73 70 71 70 66 70 71 71 70 73 71 71 70 70 70 71 73 70 71 70 66 70 71 71 70 71 71 71 70 70 70 71
				71 70 71 71 71 66 70 70 71 71 71 71 71 73 71 71 71 71 71 71 71 66 70 71 71 71 71 71 71 73 71 73
				73 71 70 71 70 66 70 71 70 71 73 71 71 70 70 71 71 73 70 71 70 66 70 71 70 71 71 71 71 70 70 71
				70 70 70 71 71 71 66 70 73 71 71 71 71 71 73 71 70 70 70 71 70 71 66 70 73 71 71 71 71 71 73 73
				71 71 71 70 71 70 66 70 71 70 71 73 71 71 70 70 71 71 73 70 71 70 66 70 70 70 71 71 71 71 70 71
				73 70 70 70 71 71 71 66 71 73 71 71 71 71 71 73 71 70 70 70 71 70 71 66 71 73 71 71 71 71 71 74
				71 70 71 71 70 71 70 66 73 71 70 71 73 71 71 70 70 71 71 71 70 71 70 66 73 71 70 71 71 71 71 71
				73 71 70 70 70 71 71 71 71 71 73 71 71 71 71 71 71 71 70 70 70 71 71 71 71 71 73 71 71 71 71 73
				73 70 70 71 71 70 71 70 73 73 71 70 71 73 71 71 71 70 71 71 71 70 71 70 71 73 71 70 71 71 71 73
				73 71 71 70 70 70 73 71 71 71 71 73 71 71 71 71 73 71 71 70 70 70 71 70 71 71 71 73 71 71 71 73
				71 71 70 71 71 71 70 71 71 73 73 71 70 71 73 71 70 71 70 70 71 71 70 71 70 73 73 71 71 71 71 73
				74 71 71 71 70 70 71 71 73 73 71 71 73 71 71 71 73 73 71 71 70 70 70 71 71 71 71 71 73 71 71 73
				71 70 71 70 71 73 73 70 71 71 73 73 71 70 71 73 70 70 71 70 70 71 73 70 71 71 73 73 71 71 71 73
				71 73 71 71 71 70 70 70 73 73 71 71 71 73 71 71 70 73 73 71 71 70 70 70 71 73 71 71 71 73 71 73
				73 71 70 71 70 71 73 73 71 71 71 73 73 71 70 71 71 70 70 71 70 70 71 71 71 71 70 73 73 71 71 73
				71 70 73 71 71 71 70 70 73 73 73 71 71 71 73 73 70 70 73 73 71 71 70 70 73 71 73 71 71 71 73 74
				73 73 71 70 71 70 71 73 71 71 71 71 73 73 71 70 73 71 70 70 71 70 71 71 71 71 71 71 73 73 71 73
				74 70 70 73 73 71 71 70 71 73 73 73 73 71 71 73 73 70 70 73 73 71 71 70 71 73 71 73 71 71 71 74
				71 71 73 71 70 71 70 71 73 71 71 71 71 73 73 71 71 71 71 70 70 71 70 71 73 71 71 71 71 73 73 73
				73 73 71 70 73 73 71 71 71 71 73 73 73 73 71 71 73 73 70 70 73 73 71 71 71 71 73 73 73 71 71 73
				73 70 71 73 71 70 71 70 73 73 71 71 71 71 73 73 71 71 71 73 71 71 71 70 73 73 71 71 71 71 73 74
				74 73 73 71 70 73 73 71 71 73 71 73 73 73 73 71 73 73 73 71 70 73 73 71 71 71 71 73 73 73 71 73
				73 71 71 71 73 71 70 71 73 73 73 71 71 71 71 73 71 71 71 71 71 71 71 71 73 73 73 71 71 71 71 74
				73 73 73 73 71 70 73 73 73 71 73 73 73 73 73 73 71 73 73 73 71 70 73 73 73 71 71 71 73 73 73 73
				74 71 71 71 71 73 71 70 71 73 73 73 71 71 71 71 73 71 71 71 71 73 71 71 71 73 73 73 71 71 71 73
				73 71 73 73 73 71 70 73 73 73 71 73 73 73 73 73 71 71 73 73 73 71 70 73 73 73 71 71 71 73 73 74
				73 73 71 71 71 71 73 71 70 71 73 73 73 71 71 71 73 73 71 71 71 71 73 71 70 71 73 73 73 71 71 73
				73 71 71 73 73 73 71 70 67 73 73 71 73 73 73 73 71 71 73 73 73 73 71 70 67 73 73 71 71 73 73 74
				73 73 73 71 71 71 71 73 67 70 71 73 73 73 71 71 71 73 73 71 73 71 71 73 66 70 71 73 73 73 71 73
				74 71 71 71 73 73 73 71 73 67 73 73 73 73 73 74 73 71 71 73 73 73 73 71 73 67 73 73 71 73 73 74
				73 71 73 73 71 71 71 71 71 67 70 71 73 73 73 71 71 71 73 73 71 73 71 71 71 66 70 71 73 73 73 73
				73 73 71 71 71 73 73 73 73 73 67 73 73 73 73 73 73 73 71 71 73 73 73 73 73 73 67 73 73 71 73 73
				73 71 71 73 73 71 71 71 73 71 67 70 71 73 73 74 73 71 71 73 73 71 73 71 71 71 66 70 71 73 73 74
				74 73 73 71 71 71 73 73 71 73 73 67 73 73 73 73 73 73 73 71 71 71 73 73 73 73 73 67 73 73 71 73
				73 71 71 71 73 73 71 71 73 71 71 67 70 71 73 73 71 73 71 71 73 73 71 73 71 71 71 66 70 71 73 74
				74 73 73 73 71 71 71 73 71 71 73 73 67 73 73 73 74 73 73 73 71 71 73 73 73 73 71 73 67 73 73 73
				73 71 71 71 71 71 73 71 71 71 71 71 66 70 71 74 73 71 73 71 71 73 73 71 71 71 71 71 66 70 71 74
				71 73 73 71 73 71 71 71 71 71 71 71 73 67 71 73 71 73 73 71 73 71 71 71 71 71 71 71 73 67 71 74
				74 71 71 71 70 71 71 73 70 71 71 71 70 66 70 73 74 71 71 71 71 71 73 73 71 71 71 71 70 66 69 74
				71 70 73 73 71 73 71 71 71 71 71 71 71 73 66 73 70 71 73 73 71 73 71 71 71 71 71 71 71 73 66 74
				71 71 71 71 71 71 71 73 71 71 71 71 71 71 67 71 71 73 73 71 71 71 71 73 71 71 71 71 71 71 66 71
				314 314 314>;

			PS_Config_Lmt_FW_CC_N = <
				34 29 32 32 32 32 32 32 32 32 32 32 32 32 32 33 34 29 32 32 33 32 32 32 32 32 32 32 32 32 32 34
				32 29 31 32 31 31 31 31 32 31 31 31 31 31 32 31 31 29 31 32 32 31 32 31 32 31 31 31 31 31 31 32
				32 32 29 31 31 32 32 32 32 32 32 31 32 32 32 32 32 32 29 31 31 32 32 32 32 32 32 32 32 31 32 32
				32 31 29 31 32 32 31 31 32 32 31 31 31 31 32 32 32 31 29 31 32 32 31 32 32 32 31 31 31 31 31 32
				32 31 32 29 31 31 32 32 32 32 32 32 32 32 32 32 32 32 32 29 31 31 32 32 32 32 32 32 32 32 32 32
				32 32 31 29 31 32 32 32 32 32 32 31 31 31 32 32 31 32 31 29 31 32 32 31 32 32 32 31 31 31 31 32
				32 32 31 32 29 31 31 32 32 32 32 32 32 32 32 32 32 32 32 32 29 31 31 32 32 32 32 32 32 32 32 32
				32 31 32 31 29 31 32 32 31 32 32 32 31 31 31 32 32 31 32 31 29 31 32 32 31 32 32 32 31 31 31 32
				32 31 32 32 32 29 31 31 32 32 32 32 32 32 32 32 32 32 32 32 32 29 31 32 32 32 32 32 32 32 32 32
				32 32 31 32 31 29 31 32 31 32 32 32 32 31 31 32 32 32 31 32 31 29 31 32 31 32 32 32 32 31 31 32
				31 31 31 32 32 32 29 31 32 32 32 32 32 32 32 32 31 31 31 32 31 32 29 31 32 32 32 32 32 32 32 32
				32 32 32 31 32 31 29 31 32 31 32 32 32 32 31 31 32 32 32 31 32 31 29 31 31 31 32 32 32 32 31 32
				32 31 31 31 32 32 32 29 32 32 32 32 32 32 32 32 32 31 31 31 32 31 32 29 32 32 32 32 32 32 32 33
				32 31 32 32 31 32 31 29 32 32 31 32 32 32 32 31 31 32 32 32 31 32 31 29 32 32 31 32 32 32 32 32
				32 32 31 31 31 32 32 32 32 32 32 32 32 32 32 32 32 32 31 31 31 32 32 32 32 32 32 32 32 32 32 32
				32 31 31 32 32 31 32 31 32 32 32 31 32 32 32 32 32 31 32 32 32 31 32 31 32 32 32 31 32 32 32 32
				32 32 32 31 31 31 32 32 32 32 32 32 32 32 32 32 32 32 32 31 31 31 32 31 32 32 32 32 32 32 32 32
				32 32 31 32 32 32 31 32 32 32 32 32 31 32 32 32 31 32 31 31 32 32 31 32 31 32 32 32 32 32 32 32
				33 32 32 32 31 31 32 32 32 32 32 32 32 32 32 32 32 32 32 32 31 31 31 32 32 32 32 32 32 32 32 32
				32 31 32 31 32 32 32 31 32 32 32 32 32 31 32 32 31 31 32 31 31 32 32 31 32 32 32 32 32 32 32 32
				32 32 32 32 32 31 31 31 32 32 32 32 32 32 32 32 31 32 32 32 32 31 31 31 32 32 32 32 32 32 32 32
				32 32 31 32 31 32 32 32 32 32 32 32 32 32 31 32 32 31 31 32 31 31 32 32 32 32 31 32 32 32 32 32
				32 31 32 32 32 32 31 31 32 32 32 32 32 32 32 32 31 31 32 32 32 32 31 31 32 32 32 32 32 32 32 33
				32 32 32 31 32 31 32 32 32 32 32 32 32 32 32 31 32 32 31 31 32 31 32 32 32 32 32 32 32 32 32 32
				33 31 31 32 32 32 32 31 32 32 32 32 32 32 32 32 32 31 31 32 32 32 32 31 32 32 32 32 32 32 32 33
				32 32 32 32 31 32 31 32 32 32 32 32 32 32 32 32 32 32 32 31 31 32 31 32 32 32 32 32 32 32 32 32
				32 32 32 31 32 32 32 32 32 32 32 32 32 32 32 32 32 32 31 31 32 32 32 32 32 32 32 32 32 32 32 32
				32 31 32 32 32 31 32 31 32 32 32 32 32 32 32 32 32 32 32 32 32 32 32 31 32 32 32 32 32 32 32 33
				33 32 32 32 31 32 32 32 32 32 32 32 32 32 32 32 32 32 32 32 31 32 32 32 32 32 32 32 32 32 32 32
				32 32 32 32 32 32 31 32 32 32 32 32 32 32 32 32 32 32 32 32 32 32 32 32 32 32 32 32 32 32 32 33
				32 32 32 32 32 31 32 32 32 32 32 32 32 32 32 32 32 32 32 32 32 31 32 32 32 32 32 32 32 32 32 32
				33 32 32 32 32 32 32 31 32 32 32 32 32 32 32 32 32 32 32 32 32 32 32 32 32 32 32 32 32 32 32 32
				32 32 32 32 32 32 31 32 32 32 32 32 32 32 32 32 32 32 32 32 32 32 31 32 32 32 32 32 32 32 32 33
				32 32 32 32 32 32 32 32 31 32 32 32 32 32 32 32 32 32 32 32 32 32 32 32 31 32 32 32 32 32 32 32
				32 32 32 32 32 32 32 31 30 32 32 32 32 32 32 32 32 32 32 32 32 32 32 31 30 32 32 32 32 32 32 33
				32 32 32 32 32 32 32 32 30 31 32 32 32 32 32 32 32 32 32 32 32 32 32 32 29 31 32 32 32 32 32 32
				33 32 32 32 32 32 32 32 32 30 32 32 32 32 32 33 32 32 32 32 32 32 32 32 32 30 32 32 32 32 32 33
				32 32 32 32 32 32 32 32 32 30 31 32 32 32 32 32 32 32 32 32 32 32 32 32 32 29 31 32 32 32 32 32
				32 32 32 32 32 32 32 32 32 32 30 32 32 32 32 32 32 32 32 32 32 32 32 32 32 32 30 32 32 32 32 32
				32 32 32 32 32 32 32 32 32 32 30 31 32 32 32 33 32 32 32 32 32 32 32 32 32 32 29 31 32 32 32 33
				33 32 32 32 32 32 32 32 32 32 32 30 32 32 32 32 32 32 32 32 32 32 32 32 32 32 32 30 32 32 32 32
				32 32 32 32 32 32 32 32 32 32 32 30 31 32 32 32 32 32 32 32 32 32 32 32 32 32 32 29 31 32 32 33
				33 32 32 32 32 32 32 32 32 32 32 32 30 32 32 32 33 32 32 32 32 32 32 32 32 32 32 32 30 32 32 32
				32 32 32 32 32 32 32 32 32 32 32 32 29 31 32 33 32 32 32 32 32 32 32 32 32 32 32 32 29 31 32 33
				32 32 32 32 32 32 32 32 32 32 32 32 32 30 32 32 32 32 32 32 32 32 32 32 32 32 32 32 32 30 32 33
				33 32 32 32 31 32 32 32 31 32 32 32 31 29 31 32 33 32 32 32 32 32 32 32 32 32 32 32 31 29 31 33
				32 31 32 32 32 32 32 32 32 32 32 32 32 32 29 32 31 32 32 32 32 32 32 32 32 32 32 32 32 32 29 33
				32 32 32 32 32 32 32 32 32 32 32 32 32 32 30 32 32 32 32 32 32 32 32 32 32 32 32 32 32 32 29 32
				0 0 0>;

			PS_Config_Lmt_FW_Diff_P = <
				50 50 50 50 50 50 50 50 50 50 50 50 50 50 50 50 50 50 50 50 50 50 50 50 50 50 50 50 50 50 50 50
				50 50 50 50 50 50 50 50 50 50 50 50 50 50 50 50 50 50 50 50 50 50 50 50 50 50 50 50 50 50 50 50
				50 50 50 50 50 50 50 50 50 50 50 50 50 50 50 50 50 50 50 50 50 50 50 50 50 50 50 50 50 50 50 50
				50 50 50 50 50 50 50 50 50 50 50 50 50 50 50 50 50 50 50 50 50 50 50 50 50 50 50 50 50 50 50 50
				50 50 50 50 50 50 50 50 50 50 50 50 50 50 50 50 50 50 50 50 50 50 50 50 50 50 50 50 50 50 50 50
				50 50 50 50 50 50 50 50 50 50 50 50 50 50 50 50 50 50 50 50 50 50 50 50 50 50 50 50 50 50 50 50
				50 50 50 50 50 50 50 50 50 50 50 50 50 50 50 50 50 50 50 50 50 50 50 50 50 50 50 50 50 50 50 50
				50 50 50 50 50 50 50 50 50 50 50 50 50 50 50 50 50 50 50 50 50 50 50 50 50 50 50 50 50 50 50 50
				50 50 50 50 50 50 50 50 50 50 50 50 50 50 50 50 50 50 50 50 50 50 50 50 50 50 50 50 50 50 50 50
				50 50 50 50 50 50 50 50 50 50 50 50 50 50 50 50 50 50 50 50 50 50 50 50 50 50 50 50 50 50 50 50
				50 50 50 50 50 50 50 50 50 50 50 50 50 50 50 50 50 50 50 50 50 50 50 50 50 50 50 50 50 50 50 50
				50 50 50 50 50 50 50 50 50 50 50 50 50 50 50 50 50 50 50 50 50 50 50 50 50 50 50 50 50 50 50 50
				50 50 50 50 50 50 50 50 50 50 50 50 50 50 50 50 50 50 50 50 50 50 50 50 50 50 50 50 50 50 50 50
				50 50 50 50 50 50 50 50 50 50 50 50 50 50 50 50 50 50 50 50 50 50 50 50 50 50 50 50 50 50 50 50
				50 50 50 50 50 50 50 50 50 50 50 50 50 50 50 50 50 50 50 50 50 50 50 50 50 50 50 50 50 50 50 50
				50 50 50 50 50 50 50 50 50 50 50 50 50 50 50 50 50 50 50 50 50 50 50 50 50 50 50 50 50 50 50 50
				50 50 50 50 50 50 50 50 50 50 50 50 50 50 50 50 50 50 50 50 50 50 50 50 50 50 50 50 50 50 50 50
				50 50 50 50 50 50 50 50 50 50 50 50 50 50 50 50 50 50 50 50 50 50 50 50 50 50 50 50 50 50 50 50
				50 50 50 50 50 50 50 50 50 50 50 50 50 50 50 50 50 50 50 50 50 50 50 50 50 50 50 50 50 50 50 50
				50 50 50 50 50 50 50 50 50 50 50 50 50 50 50 50 50 50 50 50 50 50 50 50 50 50 50 50 50 50 50 50
				50 50 50 50 50 50 50 50 50 50 50 50 50 50 50 50 50 50 50 50 50 50 50 50 50 50 50 50 50 50 50 50
				50 50 50 50 50 50 50 50 50 50 50 50 50 50 50 50 50 50 50 50 50 50 50 50 50 50 50 50 50 50 50 50
				50 50 50 50 50 50 50 50 50 50 50 50 50 50 50 50 50 50 50 50 50 50 50 50 50 50 50 50 50 50 50 50
				50 50 50 50 50 50 50 50 50 50 50 50 50 50 50 50 50 50 50 50 50 50 50 50 50 50 50 50 50 50 50 50
				50 50 50 50 50 50 50 50 50 50 50 50 50 50 50 50 50 50 50 50 50 50 50 50 50 50 50 50 50 50 50 50
				50 50 50 50 50 50 50 50 50 50 50 50 50 50 50 50 50 50 50 50 50 50 50 50 50 50 50 50 50 50 50 50
				50 50 50 50 50 50 50 50 50 50 50 50 50 50 50 50 50 50 50 50 50 50 50 50 50 50 50 50 50 50 50 50
				50 50 50 50 50 50 50 50 50 50 50 50 50 50 50 50 50 50 50 50 50 50 50 50 50 50 50 50 50 50 50 50
				50 50 50 50 50 50 50 50 50 50 50 50 50 50 50 50 50 50 50 50 50 50 50 50 50 50 50 50 50 50 50 50
				50 50 50 50 50 50 50 50 50 50 50 50 50 50 50 50 50 50 50 50 50 50 50 50 50 50 50 50 50 50 50 50
				50 50 50 50 50 50 50 50 50 50 50 50 50 50 50 50 50 50 50 50 50 50 50 50 50 50 50 50 50 50 50 50
				50 50 50 50 50 50 50 50 50 50 50 50 50 50 50 50 50 50 50 50 50 50 50 50 50 50 50 50 50 50 50 50
				50 50 50 50 50 50 50 50 50 50 50 50 50 50 50 50 50 50 50 50 50 50 50 50 50 50 50 50 50 50 50 50
				50 50 50 50 50 50 50 50 50 50 50 50 50 50 50 50 50 50 50 50 50 50 50 50 50 50 50 50 50 50 50 50
				50 50 50 50 50 50 50 50 50 50 50 50 50 50 50 50 50 50 50 50 50 50 50 50 50 50 50 50 50 50 50 50
				50 50 50 50 50 50 50 50 50 50 50 50 50 50 50 50 50 50 50 50 50 50 50 50 50 50 50 50 50 50 50 50
				50 50 50 50 50 50 50 50 50 50 50 50 50 50 50 50 50 50 50 50 50 50 50 50 50 50 50 50 50 50 50 50
				50 50 50 50 50 50 50 50 50 50 50 50 50 50 50 50 50 50 50 50 50 50 50 50 50 50 50 50 50 50 50 50
				50 50 50 50 50 50 50 50 50 50 50 50 50 50 50 50 50 50 50 50 50 50 50 50 50 50 50 50 50 50 50 50
				50 50 50 50 50 50 50 50 50 50 50 50 50 50 50 50 50 50 50 50 50 50 50 50 50 50 50 50 50 50 50 50
				50 50 50 50 50 50 50 50 50 50 50 50 50 50 50 50 50 50 50 50 50 50 50 50 50 50 50 50 50 50 50 50
				50 50 50 50 50 50 50 50 50 50 50 50 50 50 50 50 50 50 50 50 50 50 50 50 50 50 50 50 50 50 50 50
				50 50 50 50 50 50 50 50 50 50 50 50 50 50 50 50 50 50 50 50 50 50 50 50 50 50 50 50 50 50 50 50
				50 50 50 50 50 50 50 50 50 50 50 50 50 50 50 50 50 50 50 50 50 50 50 50 50 50 50 50 50 50 50 50
				50 50 50 50 50 50 50 50 50 50 50 50 50 50 50 50 50 50 50 50 50 50 50 50 50 50 50 50 50 50 50 50
				50 50 50 50 50 50 50 50 50 50 50 50 50 50 50 50 50 50 50 50 50 50 50 50 50 50 50 50 50 50 50 50
				50 50 50 50 50 50 50 50 50 50 50 50 50 50 50 50 50 50 50 50 50 50 50 50 50 50 50 50 50 50 50 50
				50 50 50 50 50 50 50 50 50 50 50 50 50 50 50 50 50 50 50 50 50 50 50 50 50 50 50 50 50 50 50 50
				75 75 75>;

			PS_Config_Lmt_FW_Diff_N = <
				(-50) (-50) (-50) (-50) (-50) (-50) (-50) (-50) (-50) (-50) (-50) (-50) (-50) (-50) (-50) (-50) (-50) (-50) (-50) (-50) (-50) (-50) (-50) (-50) (-50) (-50) (-50) (-50) (-50) (-50) (-50) (-50)
				(-50) (-50) (-50) (-50) (-50) (-50) (-50) (-50) (-50) (-50) (-50) (-50) (-50) (-50) (-50) (-50) (-50) (-50) (-50) (-50) (-50) (-50) (-50) (-50) (-50) (-50) (-50) (-50) (-50) (-50) (-50) (-50)
				(-50) (-50) (-50) (-50) (-50) (-50) (-50) (-50) (-50) (-50) (-50) (-50) (-50) (-50) (-50) (-50) (-50) (-50) (-50) (-50) (-50) (-50) (-50) (-50) (-50) (-50) (-50) (-50) (-50) (-50) (-50) (-50)
				(-50) (-50) (-50) (-50) (-50) (-50) (-50) (-50) (-50) (-50) (-50) (-50) (-50) (-50) (-50) (-50) (-50) (-50) (-50) (-50) (-50) (-50) (-50) (-50) (-50) (-50) (-50) (-50) (-50) (-50) (-50) (-50)
				(-50) (-50) (-50) (-50) (-50) (-50) (-50) (-50) (-50) (-50) (-50) (-50) (-50) (-50) (-50) (-50) (-50) (-50) (-50) (-50) (-50) (-50) (-50) (-50) (-50) (-50) (-50) (-50) (-50) (-50) (-50) (-50)
				(-50) (-50) (-50) (-50) (-50) (-50) (-50) (-50) (-50) (-50) (-50) (-50) (-50) (-50) (-50) (-50) (-50) (-50) (-50) (-50) (-50) (-50) (-50) (-50) (-50) (-50) (-50) (-50) (-50) (-50) (-50) (-50)
				(-50) (-50) (-50) (-50) (-50) (-50) (-50) (-50) (-50) (-50) (-50) (-50) (-50) (-50) (-50) (-50) (-50) (-50) (-50) (-50) (-50) (-50) (-50) (-50) (-50) (-50) (-50) (-50) (-50) (-50) (-50) (-50)
				(-50) (-50) (-50) (-50) (-50) (-50) (-50) (-50) (-50) (-50) (-50) (-50) (-50) (-50) (-50) (-50) (-50) (-50) (-50) (-50) (-50) (-50) (-50) (-50) (-50) (-50) (-50) (-50) (-50) (-50) (-50) (-50)
				(-50) (-50) (-50) (-50) (-50) (-50) (-50) (-50) (-50) (-50) (-50) (-50) (-50) (-50) (-50) (-50) (-50) (-50) (-50) (-50) (-50) (-50) (-50) (-50) (-50) (-50) (-50) (-50) (-50) (-50) (-50) (-50)
				(-50) (-50) (-50) (-50) (-50) (-50) (-50) (-50) (-50) (-50) (-50) (-50) (-50) (-50) (-50) (-50) (-50) (-50) (-50) (-50) (-50) (-50) (-50) (-50) (-50) (-50) (-50) (-50) (-50) (-50) (-50) (-50)
				(-50) (-50) (-50) (-50) (-50) (-50) (-50) (-50) (-50) (-50) (-50) (-50) (-50) (-50) (-50) (-50) (-50) (-50) (-50) (-50) (-50) (-50) (-50) (-50) (-50) (-50) (-50) (-50) (-50) (-50) (-50) (-50)
				(-50) (-50) (-50) (-50) (-50) (-50) (-50) (-50) (-50) (-50) (-50) (-50) (-50) (-50) (-50) (-50) (-50) (-50) (-50) (-50) (-50) (-50) (-50) (-50) (-50) (-50) (-50) (-50) (-50) (-50) (-50) (-50)
				(-50) (-50) (-50) (-50) (-50) (-50) (-50) (-50) (-50) (-50) (-50) (-50) (-50) (-50) (-50) (-50) (-50) (-50) (-50) (-50) (-50) (-50) (-50) (-50) (-50) (-50) (-50) (-50) (-50) (-50) (-50) (-50)
				(-50) (-50) (-50) (-50) (-50) (-50) (-50) (-50) (-50) (-50) (-50) (-50) (-50) (-50) (-50) (-50) (-50) (-50) (-50) (-50) (-50) (-50) (-50) (-50) (-50) (-50) (-50) (-50) (-50) (-50) (-50) (-50)
				(-50) (-50) (-50) (-50) (-50) (-50) (-50) (-50) (-50) (-50) (-50) (-50) (-50) (-50) (-50) (-50) (-50) (-50) (-50) (-50) (-50) (-50) (-50) (-50) (-50) (-50) (-50) (-50) (-50) (-50) (-50) (-50)
				(-50) (-50) (-50) (-50) (-50) (-50) (-50) (-50) (-50) (-50) (-50) (-50) (-50) (-50) (-50) (-50) (-50) (-50) (-50) (-50) (-50) (-50) (-50) (-50) (-50) (-50) (-50) (-50) (-50) (-50) (-50) (-50)
				(-50) (-50) (-50) (-50) (-50) (-50) (-50) (-50) (-50) (-50) (-50) (-50) (-50) (-50) (-50) (-50) (-50) (-50) (-50) (-50) (-50) (-50) (-50) (-50) (-50) (-50) (-50) (-50) (-50) (-50) (-50) (-50)
				(-50) (-50) (-50) (-50) (-50) (-50) (-50) (-50) (-50) (-50) (-50) (-50) (-50) (-50) (-50) (-50) (-50) (-50) (-50) (-50) (-50) (-50) (-50) (-50) (-50) (-50) (-50) (-50) (-50) (-50) (-50) (-50)
				(-50) (-50) (-50) (-50) (-50) (-50) (-50) (-50) (-50) (-50) (-50) (-50) (-50) (-50) (-50) (-50) (-50) (-50) (-50) (-50) (-50) (-50) (-50) (-50) (-50) (-50) (-50) (-50) (-50) (-50) (-50) (-50)
				(-50) (-50) (-50) (-50) (-50) (-50) (-50) (-50) (-50) (-50) (-50) (-50) (-50) (-50) (-50) (-50) (-50) (-50) (-50) (-50) (-50) (-50) (-50) (-50) (-50) (-50) (-50) (-50) (-50) (-50) (-50) (-50)
				(-50) (-50) (-50) (-50) (-50) (-50) (-50) (-50) (-50) (-50) (-50) (-50) (-50) (-50) (-50) (-50) (-50) (-50) (-50) (-50) (-50) (-50) (-50) (-50) (-50) (-50) (-50) (-50) (-50) (-50) (-50) (-50)
				(-50) (-50) (-50) (-50) (-50) (-50) (-50) (-50) (-50) (-50) (-50) (-50) (-50) (-50) (-50) (-50) (-50) (-50) (-50) (-50) (-50) (-50) (-50) (-50) (-50) (-50) (-50) (-50) (-50) (-50) (-50) (-50)
				(-50) (-50) (-50) (-50) (-50) (-50) (-50) (-50) (-50) (-50) (-50) (-50) (-50) (-50) (-50) (-50) (-50) (-50) (-50) (-50) (-50) (-50) (-50) (-50) (-50) (-50) (-50) (-50) (-50) (-50) (-50) (-50)
				(-50) (-50) (-50) (-50) (-50) (-50) (-50) (-50) (-50) (-50) (-50) (-50) (-50) (-50) (-50) (-50) (-50) (-50) (-50) (-50) (-50) (-50) (-50) (-50) (-50) (-50) (-50) (-50) (-50) (-50) (-50) (-50)
				(-50) (-50) (-50) (-50) (-50) (-50) (-50) (-50) (-50) (-50) (-50) (-50) (-50) (-50) (-50) (-50) (-50) (-50) (-50) (-50) (-50) (-50) (-50) (-50) (-50) (-50) (-50) (-50) (-50) (-50) (-50) (-50)
				(-50) (-50) (-50) (-50) (-50) (-50) (-50) (-50) (-50) (-50) (-50) (-50) (-50) (-50) (-50) (-50) (-50) (-50) (-50) (-50) (-50) (-50) (-50) (-50) (-50) (-50) (-50) (-50) (-50) (-50) (-50) (-50)
				(-50) (-50) (-50) (-50) (-50) (-50) (-50) (-50) (-50) (-50) (-50) (-50) (-50) (-50) (-50) (-50) (-50) (-50) (-50) (-50) (-50) (-50) (-50) (-50) (-50) (-50) (-50) (-50) (-50) (-50) (-50) (-50)
				(-50) (-50) (-50) (-50) (-50) (-50) (-50) (-50) (-50) (-50) (-50) (-50) (-50) (-50) (-50) (-50) (-50) (-50) (-50) (-50) (-50) (-50) (-50) (-50) (-50) (-50) (-50) (-50) (-50) (-50) (-50) (-50)
				(-50) (-50) (-50) (-50) (-50) (-50) (-50) (-50) (-50) (-50) (-50) (-50) (-50) (-50) (-50) (-50) (-50) (-50) (-50) (-50) (-50) (-50) (-50) (-50) (-50) (-50) (-50) (-50) (-50) (-50) (-50) (-50)
				(-50) (-50) (-50) (-50) (-50) (-50) (-50) (-50) (-50) (-50) (-50) (-50) (-50) (-50) (-50) (-50) (-50) (-50) (-50) (-50) (-50) (-50) (-50) (-50) (-50) (-50) (-50) (-50) (-50) (-50) (-50) (-50)
				(-50) (-50) (-50) (-50) (-50) (-50) (-50) (-50) (-50) (-50) (-50) (-50) (-50) (-50) (-50) (-50) (-50) (-50) (-50) (-50) (-50) (-50) (-50) (-50) (-50) (-50) (-50) (-50) (-50) (-50) (-50) (-50)
				(-50) (-50) (-50) (-50) (-50) (-50) (-50) (-50) (-50) (-50) (-50) (-50) (-50) (-50) (-50) (-50) (-50) (-50) (-50) (-50) (-50) (-50) (-50) (-50) (-50) (-50) (-50) (-50) (-50) (-50) (-50) (-50)
				(-50) (-50) (-50) (-50) (-50) (-50) (-50) (-50) (-50) (-50) (-50) (-50) (-50) (-50) (-50) (-50) (-50) (-50) (-50) (-50) (-50) (-50) (-50) (-50) (-50) (-50) (-50) (-50) (-50) (-50) (-50) (-50)
				(-50) (-50) (-50) (-50) (-50) (-50) (-50) (-50) (-50) (-50) (-50) (-50) (-50) (-50) (-50) (-50) (-50) (-50) (-50) (-50) (-50) (-50) (-50) (-50) (-50) (-50) (-50) (-50) (-50) (-50) (-50) (-50)
				(-50) (-50) (-50) (-50) (-50) (-50) (-50) (-50) (-50) (-50) (-50) (-50) (-50) (-50) (-50) (-50) (-50) (-50) (-50) (-50) (-50) (-50) (-50) (-50) (-50) (-50) (-50) (-50) (-50) (-50) (-50) (-50)
				(-50) (-50) (-50) (-50) (-50) (-50) (-50) (-50) (-50) (-50) (-50) (-50) (-50) (-50) (-50) (-50) (-50) (-50) (-50) (-50) (-50) (-50) (-50) (-50) (-50) (-50) (-50) (-50) (-50) (-50) (-50) (-50)
				(-50) (-50) (-50) (-50) (-50) (-50) (-50) (-50) (-50) (-50) (-50) (-50) (-50) (-50) (-50) (-50) (-50) (-50) (-50) (-50) (-50) (-50) (-50) (-50) (-50) (-50) (-50) (-50) (-50) (-50) (-50) (-50)
				(-50) (-50) (-50) (-50) (-50) (-50) (-50) (-50) (-50) (-50) (-50) (-50) (-50) (-50) (-50) (-50) (-50) (-50) (-50) (-50) (-50) (-50) (-50) (-50) (-50) (-50) (-50) (-50) (-50) (-50) (-50) (-50)
				(-50) (-50) (-50) (-50) (-50) (-50) (-50) (-50) (-50) (-50) (-50) (-50) (-50) (-50) (-50) (-50) (-50) (-50) (-50) (-50) (-50) (-50) (-50) (-50) (-50) (-50) (-50) (-50) (-50) (-50) (-50) (-50)
				(-50) (-50) (-50) (-50) (-50) (-50) (-50) (-50) (-50) (-50) (-50) (-50) (-50) (-50) (-50) (-50) (-50) (-50) (-50) (-50) (-50) (-50) (-50) (-50) (-50) (-50) (-50) (-50) (-50) (-50) (-50) (-50)
				(-50) (-50) (-50) (-50) (-50) (-50) (-50) (-50) (-50) (-50) (-50) (-50) (-50) (-50) (-50) (-50) (-50) (-50) (-50) (-50) (-50) (-50) (-50) (-50) (-50) (-50) (-50) (-50) (-50) (-50) (-50) (-50)
				(-50) (-50) (-50) (-50) (-50) (-50) (-50) (-50) (-50) (-50) (-50) (-50) (-50) (-50) (-50) (-50) (-50) (-50) (-50) (-50) (-50) (-50) (-50) (-50) (-50) (-50) (-50) (-50) (-50) (-50) (-50) (-50)
				(-50) (-50) (-50) (-50) (-50) (-50) (-50) (-50) (-50) (-50) (-50) (-50) (-50) (-50) (-50) (-50) (-50) (-50) (-50) (-50) (-50) (-50) (-50) (-50) (-50) (-50) (-50) (-50) (-50) (-50) (-50) (-50)
				(-50) (-50) (-50) (-50) (-50) (-50) (-50) (-50) (-50) (-50) (-50) (-50) (-50) (-50) (-50) (-50) (-50) (-50) (-50) (-50) (-50) (-50) (-50) (-50) (-50) (-50) (-50) (-50) (-50) (-50) (-50) (-50)
				(-50) (-50) (-50) (-50) (-50) (-50) (-50) (-50) (-50) (-50) (-50) (-50) (-50) (-50) (-50) (-50) (-50) (-50) (-50) (-50) (-50) (-50) (-50) (-50) (-50) (-50) (-50) (-50) (-50) (-50) (-50) (-50)
				(-50) (-50) (-50) (-50) (-50) (-50) (-50) (-50) (-50) (-50) (-50) (-50) (-50) (-50) (-50) (-50) (-50) (-50) (-50) (-50) (-50) (-50) (-50) (-50) (-50) (-50) (-50) (-50) (-50) (-50) (-50) (-50)
				(-50) (-50) (-50) (-50) (-50) (-50) (-50) (-50) (-50) (-50) (-50) (-50) (-50) (-50) (-50) (-50) (-50) (-50) (-50) (-50) (-50) (-50) (-50) (-50) (-50) (-50) (-50) (-50) (-50) (-50) (-50) (-50)
				(-50) (-50) (-50) (-50) (-50) (-50) (-50) (-50) (-50) (-50) (-50) (-50) (-50) (-50) (-50) (-50) (-50) (-50) (-50) (-50) (-50) (-50) (-50) (-50) (-50) (-50) (-50) (-50) (-50) (-50) (-50) (-50)
				(-75) (-75) (-75)>;

			PS_Config_Lmt_PenTipX_FW_Raw_P = <
				380 380 380 380 380 380 380 380 380 380 380 380 380 380 380 380 380 380 380 380 380 380 380 380 380 380 380 380 380 380 380 380
				380 380 380 380 380 380 380 380 380 380 380 380 380 380 380 380 380 380 380 380 380 380 380 380 380 380 380 380 380 380 380 380
				380 380 380 380 380 380 380 380 380 380 380 380 380 380 380 380 380 380 380 380 380 380 380 380 380 380 380 380 380 380 380 380
				380 380 380 380 380 380 380 380 380 380 380 380 380 380 380 380 380 380 380 380 380 380 380 380 380 380 380 380 380 380 380 380
				380 380 380 380 380 380 380 380 380 380 380 380 380 380 380 380 380 380 380 380 380 380 380 380 380 380 380 380 380 380 380 380
				380 380 380 380 380 380 380 380 380 380 380 380 380 380 380 380 380 380 380 380 380 380 380 380 380 380 380 380 380 380 380 380>;

			PS_Config_Lmt_PenTipX_FW_Raw_N = <
				0 0 0 0 0 0 0 0 0 0 0 0 0 0 0 0 0 0 0 0 0 0 0 0 0 0 0 0 0 0 0 0
				0 0 0 0 0 0 0 0 0 0 0 0 0 0 0 0 0 0 0 0 0 0 0 0 0 0 0 0 0 0 0 0
				0 0 0 0 0 0 0 0 0 0 0 0 0 0 0 0 0 0 0 0 0 0 0 0 0 0 0 0 0 0 0 0
				0 0 0 0 0 0 0 0 0 0 0 0 0 0 0 0 0 0 0 0 0 0 0 0 0 0 0 0 0 0 0 0
				0 0 0 0 0 0 0 0 0 0 0 0 0 0 0 0 0 0 0 0 0 0 0 0 0 0 0 0 0 0 0 0
				0 0 0 0 0 0 0 0 0 0 0 0 0 0 0 0 0 0 0 0 0 0 0 0 0 0 0 0 0 0 0 0>;

			PS_Config_Lmt_PenTipY_FW_Raw_P = <
				380 380 380 380
				380 380 380 380
				380 380 380 380
				380 380 380 380
				380 380 380 380
				380 380 380 380
				380 380 380 380
				380 380 380 380
				380 380 380 380
				380 380 380 380
				380 380 380 380
				380 380 380 380
				380 380 380 380
				380 380 380 380
				380 380 380 380
				380 380 380 380
				380 380 380 380
				380 380 380 380
				380 380 380 380
				380 380 380 380
				380 380 380 380
				380 380 380 380
				380 380 380 380
				380 380 380 380
				380 380 380 380
				380 380 380 380
				380 380 380 380
				380 380 380 380
				380 380 380 380
				380 380 380 380
				380 380 380 380
				380 380 380 380
				380 380 380 380
				380 380 380 380
				380 380 380 380
				380 380 380 380
				380 380 380 380
				380 380 380 380
				380 380 380 380
				380 380 380 380
				380 380 380 380
				380 380 380 380
				380 380 380 380
				380 380 380 380
				380 380 380 380
				380 380 380 380
				380 380 380 380
				380 380 380 380>;

			PS_Config_Lmt_PenTipY_FW_Raw_N = <
				0 0 0 0
				0 0 0 0
				0 0 0 0
				0 0 0 0
				0 0 0 0
				0 0 0 0
				0 0 0 0
				0 0 0 0
				0 0 0 0
				0 0 0 0
				0 0 0 0
				0 0 0 0
				0 0 0 0
				0 0 0 0
				0 0 0 0
				0 0 0 0
				0 0 0 0
				0 0 0 0
				0 0 0 0
				0 0 0 0
				0 0 0 0
				0 0 0 0
				0 0 0 0
				0 0 0 0
				0 0 0 0
				0 0 0 0
				0 0 0 0
				0 0 0 0
				0 0 0 0
				0 0 0 0
				0 0 0 0
				0 0 0 0
				0 0 0 0
				0 0 0 0
				0 0 0 0
				0 0 0 0
				0 0 0 0
				0 0 0 0
				0 0 0 0
				0 0 0 0
				0 0 0 0
				0 0 0 0
				0 0 0 0
				0 0 0 0
				0 0 0 0
				0 0 0 0
				0 0 0 0
				0 0 0 0>;

			PS_Config_Lmt_PenRingX_FW_Raw_P = <
				380 380 380 380 380 380 380 380 380 380 380 380 380 380 380 380 380 380 380 380 380 380 380 380 380 380 380 380 380 380 380 380
				380 380 380 380 380 380 380 380 380 380 380 380 380 380 380 380 380 380 380 380 380 380 380 380 380 380 380 380 380 380 380 380
				380 380 380 380 380 380 380 380 380 380 380 380 380 380 380 380 380 380 380 380 380 380 380 380 380 380 380 380 380 380 380 380
				380 380 380 380 380 380 380 380 380 380 380 380 380 380 380 380 380 380 380 380 380 380 380 380 380 380 380 380 380 380 380 380
				380 380 380 380 380 380 380 380 380 380 380 380 380 380 380 380 380 380 380 380 380 380 380 380 380 380 380 380 380 380 380 380
				380 380 380 380 380 380 380 380 380 380 380 380 380 380 380 380 380 380 380 380 380 380 380 380 380 380 380 380 380 380 380 380>;

			PS_Config_Lmt_PenRingX_FW_Raw_N = <
				0 0 0 0 0 0 0 0 0 0 0 0 0 0 0 0 0 0 0 0 0 0 0 0 0 0 0 0 0 0 0 0
				0 0 0 0 0 0 0 0 0 0 0 0 0 0 0 0 0 0 0 0 0 0 0 0 0 0 0 0 0 0 0 0
				0 0 0 0 0 0 0 0 0 0 0 0 0 0 0 0 0 0 0 0 0 0 0 0 0 0 0 0 0 0 0 0
				0 0 0 0 0 0 0 0 0 0 0 0 0 0 0 0 0 0 0 0 0 0 0 0 0 0 0 0 0 0 0 0
				0 0 0 0 0 0 0 0 0 0 0 0 0 0 0 0 0 0 0 0 0 0 0 0 0 0 0 0 0 0 0 0
				0 0 0 0 0 0 0 0 0 0 0 0 0 0 0 0 0 0 0 0 0 0 0 0 0 0 0 0 0 0 0 0>;

			PS_Config_Lmt_PenRingY_FW_Raw_P = <
				380 380 380 380
				380 380 380 380
				380 380 380 380
				380 380 380 380
				380 380 380 380
				380 380 380 380
				380 380 380 380
				380 380 380 380
				380 380 380 380
				380 380 380 380
				380 380 380 380
				380 380 380 380
				380 380 380 380
				380 380 380 380
				380 380 380 380
				380 380 380 380
				380 380 380 380
				380 380 380 380
				380 380 380 380
				380 380 380 380
				380 380 380 380
				380 380 380 380
				380 380 380 380
				380 380 380 380
				380 380 380 380
				380 380 380 380
				380 380 380 380
				380 380 380 380
				380 380 380 380
				380 380 380 380
				380 380 380 380
				380 380 380 380
				380 380 380 380
				380 380 380 380
				380 380 380 380
				380 380 380 380
				380 380 380 380
				380 380 380 380
				380 380 380 380
				380 380 380 380
				380 380 380 380
				380 380 380 380
				380 380 380 380
				380 380 380 380
				380 380 380 380
				380 380 380 380
				380 380 380 380
				380 380 380 380>;

			PS_Config_Lmt_PenRingY_FW_Raw_N = <
				0 0 0 0
				0 0 0 0
				0 0 0 0
				0 0 0 0
				0 0 0 0
				0 0 0 0
				0 0 0 0
				0 0 0 0
				0 0 0 0
				0 0 0 0
				0 0 0 0
				0 0 0 0
				0 0 0 0
				0 0 0 0
				0 0 0 0
				0 0 0 0
				0 0 0 0
				0 0 0 0
				0 0 0 0
				0 0 0 0
				0 0 0 0
				0 0 0 0
				0 0 0 0
				0 0 0 0
				0 0 0 0
				0 0 0 0
				0 0 0 0
				0 0 0 0
				0 0 0 0
				0 0 0 0
				0 0 0 0
				0 0 0 0
				0 0 0 0
				0 0 0 0
				0 0 0 0
				0 0 0 0
				0 0 0 0
				0 0 0 0
				0 0 0 0
				0 0 0 0
				0 0 0 0
				0 0 0 0
				0 0 0 0
				0 0 0 0
				0 0 0 0
				0 0 0 0
				0 0 0 0
				0 0 0 0>;

			PS_Config_Lmt_PenTipX_FW_Diff_P = <
				580 580 580 580 580 580 580 580 580 580 580 580 580 580 580 580 580 580 580 580 580 580 580 580 580 580 580 580 580 580 580 580
				580 580 580 580 580 580 580 580 580 580 580 580 580 580 580 580 580 580 580 580 580 580 580 580 580 580 580 580 580 580 580 580
				580 580 580 580 580 580 580 580 580 580 580 580 580 580 580 580 580 580 580 580 580 580 580 580 580 580 580 580 580 580 580 580
				580 580 580 580 580 580 580 580 580 580 580 580 580 580 580 580 580 580 580 580 580 580 580 580 580 580 580 580 580 580 580 580
				580 580 580 580 580 580 580 580 580 580 580 580 580 580 580 580 580 580 580 580 580 580 580 580 580 580 580 580 580 580 580 580
				580 580 580 580 580 580 580 580 580 580 580 580 580 580 580 580 580 580 580 580 580 580 580 580 580 580 580 580 580 580 580 580>;

			PS_Config_Lmt_PenTipX_FW_Diff_N = <
				(-580) (-580) (-580) (-580) (-580) (-580) (-580) (-580) (-580) (-580) (-580) (-580) (-580) (-580) (-580) (-580) (-580) (-580) (-580) (-580) (-580) (-580) (-580) (-580) (-580) (-580) (-580) (-580) (-580) (-580) (-580) (-580)
				(-580) (-580) (-580) (-580) (-580) (-580) (-580) (-580) (-580) (-580) (-580) (-580) (-580) (-580) (-580) (-580) (-580) (-580) (-580) (-580) (-580) (-580) (-580) (-580) (-580) (-580) (-580) (-580) (-580) (-580) (-580) (-580)
				(-580) (-580) (-580) (-580) (-580) (-580) (-580) (-580) (-580) (-580) (-580) (-580) (-580) (-580) (-580) (-580) (-580) (-580) (-580) (-580) (-580) (-580) (-580) (-580) (-580) (-580) (-580) (-580) (-580) (-580) (-580) (-580)
				(-580) (-580) (-580) (-580) (-580) (-580) (-580) (-580) (-580) (-580) (-580) (-580) (-580) (-580) (-580) (-580) (-580) (-580) (-580) (-580) (-580) (-580) (-580) (-580) (-580) (-580) (-580) (-580) (-580) (-580) (-580) (-580)
				(-580) (-580) (-580) (-580) (-580) (-580) (-580) (-580) (-580) (-580) (-580) (-580) (-580) (-580) (-580) (-580) (-580) (-580) (-580) (-580) (-580) (-580) (-580) (-580) (-580) (-580) (-580) (-580) (-580) (-580) (-580) (-580)
				(-580) (-580) (-580) (-580) (-580) (-580) (-580) (-580) (-580) (-580) (-580) (-580) (-580) (-580) (-580) (-580) (-580) (-580) (-580) (-580) (-580) (-580) (-580) (-580) (-580) (-580) (-580) (-580) (-580) (-580) (-580) (-580)>;

			PS_Config_Lmt_PenTipY_FW_Diff_P = <
				580 580 580 580
				580 580 580 580
				580 580 580 580
				580 580 580 580
				580 580 580 580
				580 580 580 580
				580 580 580 580
				580 580 580 580
				580 580 580 580
				580 580 580 580
				580 580 580 580
				580 580 580 580
				580 580 580 580
				580 580 580 580
				580 580 580 580
				580 580 580 580
				580 580 580 580
				580 580 580 580
				580 580 580 580
				580 580 580 580
				580 580 580 580
				580 580 580 580
				580 580 580 580
				580 580 580 580
				580 580 580 580
				580 580 580 580
				580 580 580 580
				580 580 580 580
				580 580 580 580
				580 580 580 580
				580 580 580 580
				580 580 580 580
				580 580 580 580
				580 580 580 580
				580 580 580 580
				580 580 580 580
				580 580 580 580
				580 580 580 580
				580 580 580 580
				580 580 580 580
				580 580 580 580
				580 580 580 580
				580 580 580 580
				580 580 580 580
				580 580 580 580
				580 580 580 580
				580 580 580 580
				580 580 580 580>;

			PS_Config_Lmt_PenTipY_FW_Diff_N = <
				(-580) (-580) (-580) (-580)
				(-580) (-580) (-580) (-580)
				(-580) (-580) (-580) (-580)
				(-580) (-580) (-580) (-580)
				(-580) (-580) (-580) (-580)
				(-580) (-580) (-580) (-580)
				(-580) (-580) (-580) (-580)
				(-580) (-580) (-580) (-580)
				(-580) (-580) (-580) (-580)
				(-580) (-580) (-580) (-580)
				(-580) (-580) (-580) (-580)
				(-580) (-580) (-580) (-580)
				(-580) (-580) (-580) (-580)
				(-580) (-580) (-580) (-580)
				(-580) (-580) (-580) (-580)
				(-580) (-580) (-580) (-580)
				(-580) (-580) (-580) (-580)
				(-580) (-580) (-580) (-580)
				(-580) (-580) (-580) (-580)
				(-580) (-580) (-580) (-580)
				(-580) (-580) (-580) (-580)
				(-580) (-580) (-580) (-580)
				(-580) (-580) (-580) (-580)
				(-580) (-580) (-580) (-580)
				(-580) (-580) (-580) (-580)
				(-580) (-580) (-580) (-580)
				(-580) (-580) (-580) (-580)
				(-580) (-580) (-580) (-580)
				(-580) (-580) (-580) (-580)
				(-580) (-580) (-580) (-580)
				(-580) (-580) (-580) (-580)
				(-580) (-580) (-580) (-580)
				(-580) (-580) (-580) (-580)
				(-580) (-580) (-580) (-580)
				(-580) (-580) (-580) (-580)
				(-580) (-580) (-580) (-580)
				(-580) (-580) (-580) (-580)
				(-580) (-580) (-580) (-580)
				(-580) (-580) (-580) (-580)
				(-580) (-580) (-580) (-580)
				(-580) (-580) (-580) (-580)
				(-580) (-580) (-580) (-580)
				(-580) (-580) (-580) (-580)
				(-580) (-580) (-580) (-580)
				(-580) (-580) (-580) (-580)
				(-580) (-580) (-580) (-580)
				(-580) (-580) (-580) (-580)
				(-580) (-580) (-580) (-580)>;

			PS_Config_Lmt_PenRingX_FW_Diff_P = <
				580 580 580 580 580 580 580 580 580 580 580 580 580 580 580 580 580 580 580 580 580 580 580 580 580 580 580 580 580 580 580 580
				580 580 580 580 580 580 580 580 580 580 580 580 580 580 580 580 580 580 580 580 580 580 580 580 580 580 580 580 580 580 580 580
				580 580 580 580 580 580 580 580 580 580 580 580 580 580 580 580 580 580 580 580 580 580 580 580 580 580 580 580 580 580 580 580
				580 580 580 580 580 580 580 580 580 580 580 580 580 580 580 580 580 580 580 580 580 580 580 580 580 580 580 580 580 580 580 580
				580 580 580 580 580 580 580 580 580 580 580 580 580 580 580 580 580 580 580 580 580 580 580 580 580 580 580 580 580 580 580 580
				580 580 580 580 580 580 580 580 580 580 580 580 580 580 580 580 580 580 580 580 580 580 580 580 580 580 580 580 580 580 580 580>;

			PS_Config_Lmt_PenRingX_FW_Diff_N = <
				(-580) (-580) (-580) (-580) (-580) (-580) (-580) (-580) (-580) (-580) (-580) (-580) (-580) (-580) (-580) (-580) (-580) (-580) (-580) (-580) (-580) (-580) (-580) (-580) (-580) (-580) (-580) (-580) (-580) (-580) (-580) (-580)
				(-580) (-580) (-580) (-580) (-580) (-580) (-580) (-580) (-580) (-580) (-580) (-580) (-580) (-580) (-580) (-580) (-580) (-580) (-580) (-580) (-580) (-580) (-580) (-580) (-580) (-580) (-580) (-580) (-580) (-580) (-580) (-580)
				(-580) (-580) (-580) (-580) (-580) (-580) (-580) (-580) (-580) (-580) (-580) (-580) (-580) (-580) (-580) (-580) (-580) (-580) (-580) (-580) (-580) (-580) (-580) (-580) (-580) (-580) (-580) (-580) (-580) (-580) (-580) (-580)
				(-580) (-580) (-580) (-580) (-580) (-580) (-580) (-580) (-580) (-580) (-580) (-580) (-580) (-580) (-580) (-580) (-580) (-580) (-580) (-580) (-580) (-580) (-580) (-580) (-580) (-580) (-580) (-580) (-580) (-580) (-580) (-580)
				(-580) (-580) (-580) (-580) (-580) (-580) (-580) (-580) (-580) (-580) (-580) (-580) (-580) (-580) (-580) (-580) (-580) (-580) (-580) (-580) (-580) (-580) (-580) (-580) (-580) (-580) (-580) (-580) (-580) (-580) (-580) (-580)
				(-580) (-580) (-580) (-580) (-580) (-580) (-580) (-580) (-580) (-580) (-580) (-580) (-580) (-580) (-580) (-580) (-580) (-580) (-580) (-580) (-580) (-580) (-580) (-580) (-580) (-580) (-580) (-580) (-580) (-580) (-580) (-580)>;

			PS_Config_Lmt_PenRingY_FW_Diff_P = <
				580 580 580 580
				580 580 580 580
				580 580 580 580
				580 580 580 580
				580 580 580 580
				580 580 580 580
				580 580 580 580
				580 580 580 580
				580 580 580 580
				580 580 580 580
				580 580 580 580
				580 580 580 580
				580 580 580 580
				580 580 580 580
				580 580 580 580
				580 580 580 580
				580 580 580 580
				580 580 580 580
				580 580 580 580
				580 580 580 580
				580 580 580 580
				580 580 580 580
				580 580 580 580
				580 580 580 580
				580 580 580 580
				580 580 580 580
				580 580 580 580
				580 580 580 580
				580 580 580 580
				580 580 580 580
				580 580 580 580
				580 580 580 580
				580 580 580 580
				580 580 580 580
				580 580 580 580
				580 580 580 580
				580 580 580 580
				580 580 580 580
				580 580 580 580
				580 580 580 580
				580 580 580 580
				580 580 580 580
				580 580 580 580
				580 580 580 580
				580 580 580 580
				580 580 580 580
				580 580 580 580
				580 580 580 580>;

			PS_Config_Lmt_PenRingY_FW_Diff_N = <
				(-580) (-580) (-580) (-580)
				(-580) (-580) (-580) (-580)
				(-580) (-580) (-580) (-580)
				(-580) (-580) (-580) (-580)
				(-580) (-580) (-580) (-580)
				(-580) (-580) (-580) (-580)
				(-580) (-580) (-580) (-580)
				(-580) (-580) (-580) (-580)
				(-580) (-580) (-580) (-580)
				(-580) (-580) (-580) (-580)
				(-580) (-580) (-580) (-580)
				(-580) (-580) (-580) (-580)
				(-580) (-580) (-580) (-580)
				(-580) (-580) (-580) (-580)
				(-580) (-580) (-580) (-580)
				(-580) (-580) (-580) (-580)
				(-580) (-580) (-580) (-580)
				(-580) (-580) (-580) (-580)
				(-580) (-580) (-580) (-580)
				(-580) (-580) (-580) (-580)
				(-580) (-580) (-580) (-580)
				(-580) (-580) (-580) (-580)
				(-580) (-580) (-580) (-580)
				(-580) (-580) (-580) (-580)
				(-580) (-580) (-580) (-580)
				(-580) (-580) (-580) (-580)
				(-580) (-580) (-580) (-580)
				(-580) (-580) (-580) (-580)
				(-580) (-580) (-580) (-580)
				(-580) (-580) (-580) (-580)
				(-580) (-580) (-580) (-580)
				(-580) (-580) (-580) (-580)
				(-580) (-580) (-580) (-580)
				(-580) (-580) (-580) (-580)
				(-580) (-580) (-580) (-580)
				(-580) (-580) (-580) (-580)
				(-580) (-580) (-580) (-580)
				(-580) (-580) (-580) (-580)
				(-580) (-580) (-580) (-580)
				(-580) (-580) (-580) (-580)
				(-580) (-580) (-580) (-580)
				(-580) (-580) (-580) (-580)
				(-580) (-580) (-580) (-580)
				(-580) (-580) (-580) (-580)
				(-580) (-580) (-580) (-580)
				(-580) (-580) (-580) (-580)
				(-580) (-580) (-580) (-580)
				(-580) (-580) (-580) (-580)>;

			PS_Config_Diff_Test_Frame = <50>;
		};
	};
};
